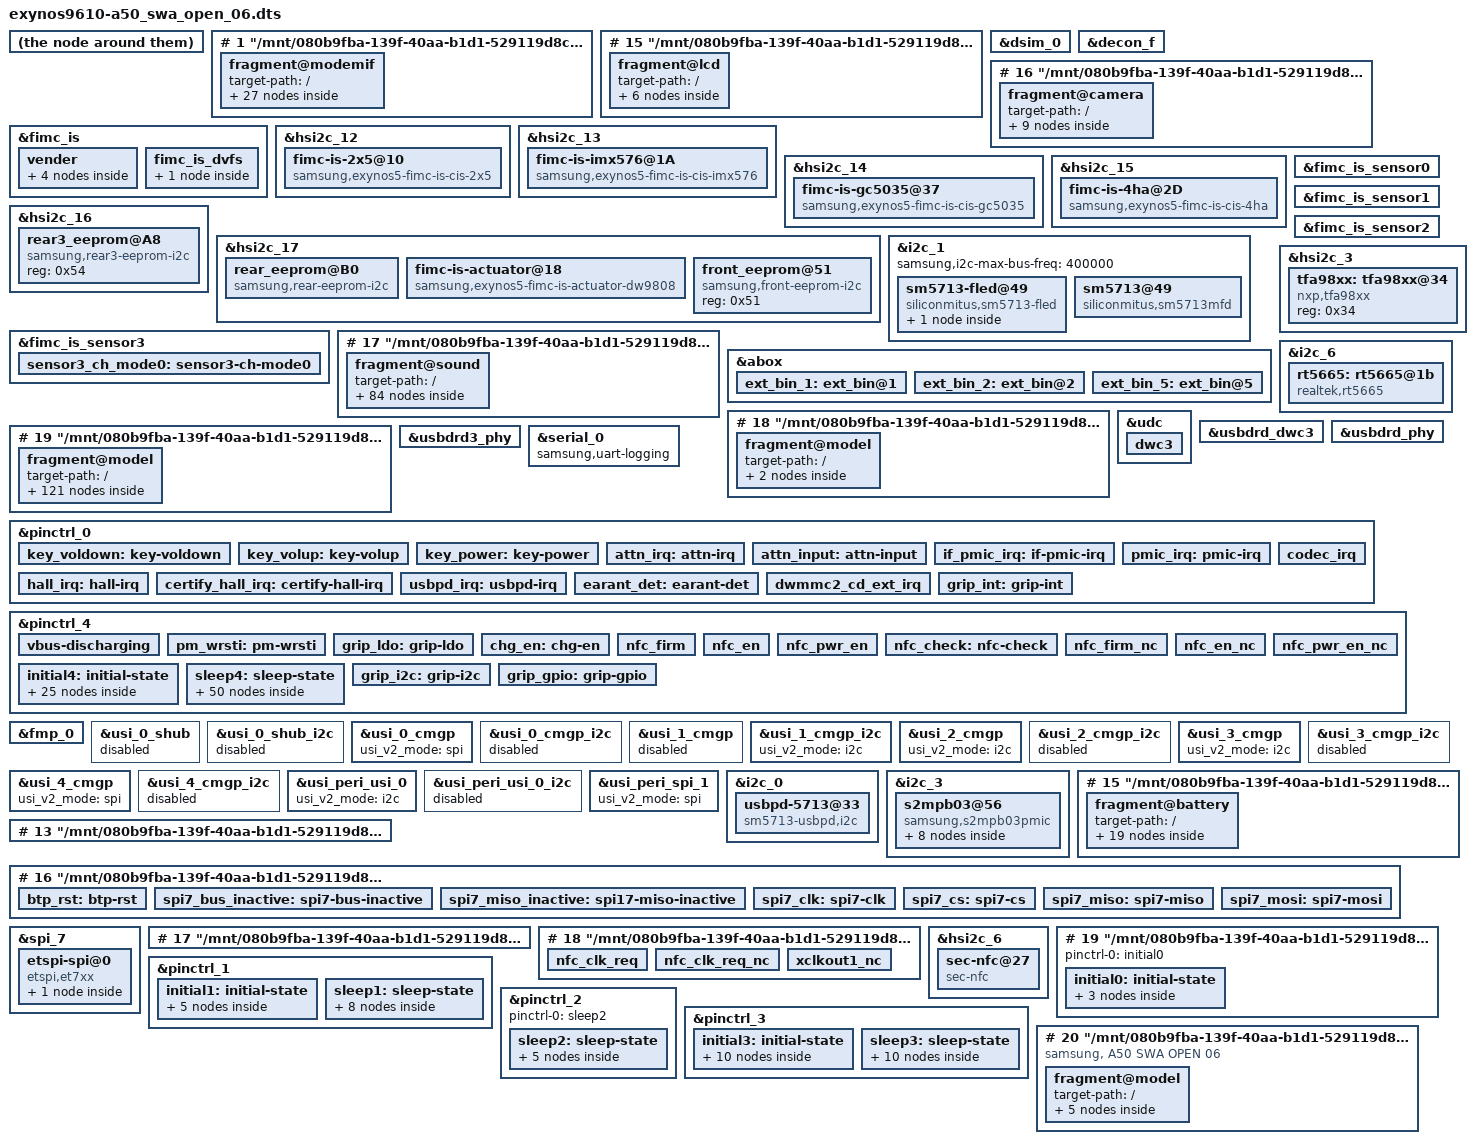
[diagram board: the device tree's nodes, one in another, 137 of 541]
# 1 "/mnt/080b9fba-139f-40aa-b1d1-529119d8c495/develop/Android/Kernel/android_kernel_samsung_universal9610/arch/arm64/boot/dts/exynos/exynos9610-a50_swa_open_06.dts"
# 1 "<built-in>"
# 1 "<command-line>"
# 1 "/mnt/080b9fba-139f-40aa-b1d1-529119d8c495/develop/Android/Kernel/android_kernel_samsung_universal9610/arch/arm64/boot/dts/exynos/exynos9610-a50_swa_open_06.dts"
# 12 "/mnt/080b9fba-139f-40aa-b1d1-529119d8c495/develop/Android/Kernel/android_kernel_samsung_universal9610/arch/arm64/boot/dts/exynos/exynos9610-a50_swa_open_06.dts"
/dts-v1/;
/plugin/;
# 1 "/mnt/080b9fba-139f-40aa-b1d1-529119d8c495/develop/Android/Kernel/android_kernel_samsung_universal9610/arch/arm64/boot/dts/exynos/exynos9610-a50_common.dtsi" 1
# 12 "/mnt/080b9fba-139f-40aa-b1d1-529119d8c495/develop/Android/Kernel/android_kernel_samsung_universal9610/arch/arm64/boot/dts/exynos/exynos9610-a50_common.dtsi"
# 1 "/mnt/080b9fba-139f-40aa-b1d1-529119d8c495/develop/Android/Kernel/android_kernel_samsung_universal9610/include/dt-bindings/camera/fimc_is.h" 1
# 13 "/mnt/080b9fba-139f-40aa-b1d1-529119d8c495/develop/Android/Kernel/android_kernel_samsung_universal9610/arch/arm64/boot/dts/exynos/exynos9610-a50_common.dtsi" 2
# 1 "/mnt/080b9fba-139f-40aa-b1d1-529119d8c495/develop/Android/Kernel/android_kernel_samsung_universal9610/include/dt-bindings/clock/exynos9610.h" 1
# 14 "/mnt/080b9fba-139f-40aa-b1d1-529119d8c495/develop/Android/Kernel/android_kernel_samsung_universal9610/arch/arm64/boot/dts/exynos/exynos9610-a50_common.dtsi" 2
# 1 "/mnt/080b9fba-139f-40aa-b1d1-529119d8c495/develop/Android/Kernel/android_kernel_samsung_universal9610/arch/arm64/boot/dts/exynos/modem-s337ap-sipc-pdata.dtsi" 1
# 12 "/mnt/080b9fba-139f-40aa-b1d1-529119d8c495/develop/Android/Kernel/android_kernel_samsung_universal9610/arch/arm64/boot/dts/exynos/modem-s337ap-sipc-pdata.dtsi"
/ {
 fragment@modemif {
  target-path = "/";
  __overlay__ {
   #address-cells = <2>;
   #size-cells = <1>;

   mif_pdata {

    reg = <0 0x10000 0x0>;

    compatible = "sec_modem,modem_pdata";
    status = "okay";
    interrupts = <0 75 0>;


    mif,name = "s337ap";
    mif,modem_net = <0>;
    mif,modem_type = <10>;
    mif,use_handover = <0>;
    mif,ipc_version = <50>;
    mif,link_types = <0x200>;
    mif,link_name = "shmem";
    mif,link_attrs = <0x7C9>;
    mif,num_iodevs = <23>;


    mif,use_usb_phy = <0>;


    mbx_ap2cp_msg = <0>;
    mbx_cp2ap_msg = <1>;
    mbx_ap2cp_united_status = <2>;
    mbx_cp2ap_united_status = <3>;
    mbx_ap2cp_mif_value = <4>;
    mbx_ap2cp_kerneltime = <9>;
    mbx_cp2ap_pcie_l1ss_disable = <17>;
    mif,int_ap2cp_msg = <0>;
    mif,int_ap2cp_wakeup = <1>;
    mif,int_ap2cp_status = <2>;
    mif,int_ap2cp_active = <3>;

    mif,irq_cp2ap_msg = <0>;
    mif,irq_cp2ap_status = <2>;
    mif,irq_cp2ap_active = <3>;
    mif,irq_cp2ap_wakelock = <8>;
    mif,irq_cp2ap_pcie_l1ss_disable = <9>;
    mif,int_ap2cp_uart_noti = <15>;


    mbx_cp2ap_dvfsreq = <4>;
    mbx_cp2ap_dvfsreq_cpu = <5>;
    mbx_cp2ap_dvfsreq_mif = <6>;
    mbx_cp2ap_dvfsreq_int = <7>;

    mif,irq_cp2ap_perf_req_cpu = <5>;
    mif,irq_cp2ap_perf_req_mif = <6>;
    mif,irq_cp2ap_perf_req_int = <7>;


    sbi_cp_rat_mode_mask = <0x3f>;
    sbi_cp_rat_mode_pos = <26>;
    sbi_cp_evs_mode_mask = <0x1>;
    sbi_cp_evs_mode_pos = <7>;
    sbi_cp2ap_wakelock_mask = <0x1>;
    sbi_cp2ap_wakelock_pos = <6>;
    sbi_lte_active_mask = <0x1>;
    sbi_lte_active_pos = <5>;
    sbi_cp_status_mask = <0xf>;
    sbi_cp_status_pos = <1>;
    sbi_pda_active_mask = <0x1>;
    sbi_pda_active_pos = <5>;
    sbi_ap_status_mask = <0xf>;
    sbi_ap_status_pos = <1>;

    sbi_crash_type_mask = <0xf>;
    sbi_crash_type_pos = <25>;
    sbi_device_type_mask = <0x1f>;
    sbi_device_type_pos = <20>;

    sbi_ext_backtrace_mask = <0x1>;
    sbi_ext_backtrace_pos = <17>;
    sbi_ds_det_mask = <0x3>;
    sbi_ds_det_pos = <14>;
    sbi_sys_rev_mask = <0xff>;
    sbi_sys_rev_pos = <6>;

    sbi_lockval_cp2ap_dvfsreq_endian_mask = <0x1>;
    sbi_lockval_cp2ap_dvfsreq_endian_pos = <31>;
    sbi_lockval_cp2ap_dvfsreq_index_mask = <0x7fff>;
    sbi_lockval_cp2ap_dvfsreq_index_pos = <0>;

    sbi_ap2cp_kerneltime_sec_mask = <0xfff>;
    sbi_ap2cp_kerneltime_sec_pos = <20>;
    sbi_ap2cp_kerneltime_usec_mask = <0xfffff>;
    sbi_ap2cp_kerneltime_usec_pos = <0>;

    sbi_uart_noti_mask = <0x1>;
    sbi_uart_noti_pos = <16>;

    iodevs {
     io_device_0 {
      iod,name = "umts_cass";
      iod,id = <35>;
      iod,format = <1>;
      iod,io_type = <0>;
      iod,links = <0x200>;
      iod,attrs = <0x82>;
      iod,max_tx_size = <2048>;
      iod,ul_num_buffers = <16>;
      iod,ul_buffer_size = <2048>;
      iod,dl_num_buffers = <16>;
      iod,dl_buffer_size = <2048>;
     };
     io_device_1 {
      iod,name = "umts_ipc0";
      iod,id = <235>;
      iod,format = <0>;
      iod,io_type = <0>;
      iod,links = <0x200>;
      iod,attrs = <0x82>;
      iod,app = "RIL";
      iod,ul_num_buffers = <16>;
      iod,ul_buffer_size = <4096>;
      iod,dl_num_buffers = <32>;
      iod,dl_buffer_size = <4096>;
     };
     io_device_2 {
      iod,name = "umts_ipc1";
      iod,id = <236>;
      iod,format = <0>;
      iod,io_type = <0>;
      iod,links = <0x200>;
      iod,attrs = <0x82>;
      iod,app = "RIL";
      iod,ul_num_buffers = <16>;
      iod,ul_buffer_size = <4096>;
      iod,dl_num_buffers = <32>;
      iod,dl_buffer_size = <4096>;
     };
     io_device_3 {
      iod,name = "umts_rfs0";
      iod,id = <245>;
      iod,format = <2>;
      iod,io_type = <0>;
      iod,links = <0x200>;
      iod,attrs = <0x82>;
      iod,app = "RFS";
      iod,ul_num_buffers = <16>;
      iod,ul_buffer_size = <2048>;
      iod,dl_num_buffers = <512>;
      iod,dl_buffer_size = <2048>;
     };
     io_device_4 {
      iod,name = "umts_csd";
      iod,id = <1>;
      iod,format = <1>;
      iod,io_type = <0>;
      iod,links = <0x200>;
      iod,attrs = <0x82>;
      iod,app = "CSVT";
      iod,ul_num_buffers = <32>;
      iod,ul_buffer_size = <2048>;
      iod,dl_num_buffers = <64>;
      iod,dl_buffer_size = <2048>;
     };
     io_device_5 {
      iod,name = "umts_router";
      iod,id = <25>;
      iod,format = <1>;
      iod,io_type = <0>;
      iod,links = <0x200>;
      iod,attrs = <0x82>;
      iod,app = "Data Router";
      iod,max_tx_size = <1550>;
      iod,ul_num_buffers = <16>;
      iod,ul_buffer_size = <2048>;
      iod,dl_num_buffers = <16>;
      iod,dl_buffer_size = <2048>;
     };
     io_device_6 {
      iod,name = "umts_dm0";
      iod,id = <28>;
      iod,format = <1>;
      iod,io_type = <0>;
      iod,links = <0x200>;
      iod,attrs = <0x82>;
      iod,app = "DIAG";
      iod,ul_num_buffers = <16>;
      iod,ul_buffer_size = <2048>;
      iod,dl_num_buffers = <128>;
      iod,dl_buffer_size = <2048>;
     };
     io_device_7 {
      iod,name = "ipc_loopback0";
      iod,id = <244>;
      iod,format = <0>;
      iod,io_type = <0>;
      iod,links = <0x200>;
      iod,attrs = <0x82>;
      iod,app = "CLD";
      iod,ul_num_buffers = <16>;
      iod,ul_buffer_size = <2048>;
      iod,dl_num_buffers = <32>;
      iod,dl_buffer_size = <2048>;
     };
     io_device_8 {
      iod,name = "rmnet0";
      iod,id = <10>;
      iod,format = <1>;
      iod,io_type = <1>;
      iod,links = <0x200>;
      iod,attrs = <0x180>;
      iod,app = "NET";
      iod,ul_num_buffers = <0>;
      iod,ul_buffer_size = <2048>;
      iod,dl_num_buffers = <0>;
      iod,dl_buffer_size = <2048>;
     };
     io_device_9 {
      iod,name = "rmnet1";
      iod,id = <11>;
      iod,format = <1>;
      iod,io_type = <1>;
      iod,links = <0x200>;
      iod,attrs = <0x180>;
      iod,app = "NET";
      iod,ul_num_buffers = <0>;
      iod,ul_buffer_size = <2048>;
      iod,dl_num_buffers = <0>;
      iod,dl_buffer_size = <2048>;
     };
     io_device_10 {
      iod,name = "rmnet2";
      iod,id = <12>;
      iod,format = <1>;
      iod,io_type = <1>;
      iod,links = <0x200>;
      iod,attrs = <0x180>;
      iod,app = "NET";
      iod,ul_num_buffers = <0>;
      iod,ul_buffer_size = <2048>;
      iod,dl_num_buffers = <0>;
      iod,dl_buffer_size = <2048>;
     };
     io_device_11 {
      iod,name = "rmnet3";
      iod,id = <13>;
      iod,format = <1>;
      iod,io_type = <1>;
      iod,links = <0x200>;
      iod,attrs = <0x180>;
      iod,app = "NET";
      iod,ul_num_buffers = <0>;
      iod,ul_buffer_size = <2048>;
      iod,dl_num_buffers = <0>;
      iod,dl_buffer_size = <2048>;
     };
     io_device_12 {
      iod,name = "rmnet4";
      iod,id = <14>;
      iod,format = <1>;
      iod,io_type = <1>;
      iod,links = <0x200>;
      iod,attrs = <0x180>;
      iod,ul_num_buffers = <0>;
      iod,ul_buffer_size = <2048>;
      iod,dl_num_buffers = <0>;
      iod,dl_buffer_size = <2048>;
     };
     io_device_13 {
      iod,name = "rmnet5";
      iod,id = <15>;
      iod,format = <1>;
      iod,io_type = <1>;
      iod,links = <0x200>;
      iod,attrs = <0x180>;
      iod,ul_num_buffers = <0>;
      iod,ul_buffer_size = <2048>;
      iod,dl_num_buffers = <0>;
      iod,dl_buffer_size = <2048>;
     };
     io_device_14 {
      iod,name = "rmnet6";
      iod,id = <16>;
      iod,format = <1>;
      iod,io_type = <1>;
      iod,links = <0x200>;
      iod,attrs = <0x180>;
      iod,ul_num_buffers = <0>;
      iod,ul_buffer_size = <2048>;
      iod,dl_num_buffers = <0>;
      iod,dl_buffer_size = <2048>;
     };
     io_device_15 {
      iod,name = "rmnet7";
      iod,id = <17>;
      iod,format = <1>;
      iod,io_type = <1>;
      iod,links = <0x200>;
      iod,attrs = <0x180>;
      iod,ul_num_buffers = <0>;
      iod,ul_buffer_size = <2048>;
      iod,dl_num_buffers = <0>;
      iod,dl_buffer_size = <2048>;
     };
     io_device_16 {
      iod,name = "multipdp_hiprio";
      iod,id = <0>;
      iod,format = <3>;
      iod,io_type = <2>;
      iod,links = <0x200>;
      iod,attrs = <0x180>;
      iod,app = "RIL";
      iod,ul_num_buffers = <256>;
      iod,ul_buffer_size = <2048>;
      iod,dl_num_buffers = <256>;
      iod,dl_buffer_size = <2048>;
     };
     io_device_17 {
      iod,name = "multipdp";
      iod,id = <0>;
      iod,format = <3>;
      iod,io_type = <2>;
      iod,links = <0x200>;
      iod,attrs = <0x180>;
      iod,app = "RIL";
      iod,ul_num_buffers = <512>;
      iod,ul_buffer_size = <2048>;
      iod,dl_num_buffers = <1024>;
      iod,dl_buffer_size = <2048>;
     };
     io_device_18 {
      iod,name = "umts_boot0";
      iod,id = <215>;
      iod,format = <4>;
      iod,io_type = <0>;
      iod,links = <0x200>;
      iod,attrs = <0x02>;
      iod,app = "CBD";
     };
     io_device_19 {
      iod,name = "umts_ramdump0";
      iod,id = <225>;
      iod,format = <5>;
      iod,io_type = <0>;
      iod,links = <0x200>;
      iod,attrs = <0x202>;
      iod,app = "CBD";
     };
     io_device_20 {
      iod,name = "umts_atc0";
      iod,id = <32>;
      iod,format = <1>;
      iod,io_type = <0>;
      iod,links = <0x200>;
      iod,attrs = <0x882>;
      iod,app = "VCD";
      iod,max_tx_size = <2048>;
      iod,ul_num_buffers = <16>;
      iod,ul_buffer_size = <2048>;
      iod,dl_num_buffers = <128>;
      iod,dl_buffer_size = <2048>;
      iod,option_region = "usa_vzw";
     };
     io_device_21 {
      iod,name = "smd4";
      iod,id = <33>;
      iod,format = <1>;
      iod,io_type = <0>;
      iod,links = <0x200>;
      iod,attrs = <0x882>;
      iod,ul_num_buffers = <16>;
      iod,ul_buffer_size = <2048>;
      iod,dl_num_buffers = <128>;
      iod,dl_buffer_size = <2048>;
      iod,option_region = "kor_single";
     };
     io_device_22 {
      iod,name = "umts_ciq0";
      iod,id = <26>;
      iod,format = <1>;
      iod,io_type = <0>;
      iod,links = <0x200>;
      iod,attrs = <0x882>;
      iod,ul_num_buffers = <16>;
      iod,ul_buffer_size = <2048>;
      iod,dl_num_buffers = <128>;
      iod,dl_buffer_size = <2048>;
      iod,option_region = "usa_spr";
     };
    };
   };

   shmem: shmem@F0000000 {
    compatible = "samsung,exynos-shm_ipc";

    shmem,cp_size = <0x7900000>;
    shmem,vss_size = <0x700000>;
    shmem,ipc_offset = <0x8000000>;
    shmem,ipc_size = <0x800000>;
   };
  };
 };
};
# 15 "/mnt/080b9fba-139f-40aa-b1d1-529119d8c495/develop/Android/Kernel/android_kernel_samsung_universal9610/arch/arm64/boot/dts/exynos/exynos9610-a50_common.dtsi" 2
# 1 "/mnt/080b9fba-139f-40aa-b1d1-529119d8c495/develop/Android/Kernel/android_kernel_samsung_universal9610/arch/arm64/boot/dts/exynos/display-lcd_a50_common.dtsi" 1
# 12 "/mnt/080b9fba-139f-40aa-b1d1-529119d8c495/develop/Android/Kernel/android_kernel_samsung_universal9610/arch/arm64/boot/dts/exynos/display-lcd_a50_common.dtsi"
/ {
 fragment@lcd {
  target-path = "/";
  __overlay__ {
   decon_board: decon_board {
    gpio_lcd_rst = <&gpg1 3 0x1>;
    gpio_lcd_en_3p0 = <&gpg2 4 0x1>;
    gpio_lcd_en_1p8 = <&gpg1 2 0x1>;

    dsim_set_panel_power_enable {
     type =
     "gpio,high", "gpio_lcd_en_1p8",
     "delay,usleep", "1000 1100",
     "gpio,high", "gpio_lcd_en_3p0",
     "delay,usleep", "10000 11000";
    };
    dsim_set_panel_power_disable {
     type =
     "gpio,low", "gpio_lcd_rst",
     "delay,usleep", "10000 11000",
     "gpio,low", "gpio_lcd_en_1p8",
     "delay,usleep", "5000 6000",
     "gpio,low", "gpio_lcd_en_3p0",
     "delay,usleep", "5000 6000";
    };
    dsim_reset_panel {
     type =
     "gpio,high", "gpio_lcd_rst",
     "delay,usleep", "1000 1100",
     "gpio,low", "gpio_lcd_rst",
     "delay,usleep", "1000 1100",
     "gpio,high", "gpio_lcd_rst",
     "delay,usleep", "10000 11000";
    };
   };

   ea8076: ea8076_fhd {
    mode = <2>;
    resolution = <1080 2340>;
    size = <68 147>;
    timing,refresh = <60>;
    timing,h-porch = <2 2 2>;
    timing,v-porch = <15 3 1>;
    timing,dsi-hs-clk = <1200>;
    timing,pmsk = <3 277 1 0>;
    timing,dsi-escape-clk = <16>;
    update_min = <1080 2>;
    mic_en = <0>;
    mic_ratio = <0>;
    mic_ver = <0>;
    type_of_ddi = <1>;
    dsc_en = <0>;
    dsc_cnt = <0>;
    dsc_slice_num = <0>;
    data_lane = <4>;
    cmd_underrun_lp_ref = <2076>;
    mres_en = <0>;
    noncontinuous_clklane = <0>;
   };
  };
 };
};

&dsim_0 {
 lcd_info = <&ea8076>;
 decon_board = <&decon_board>;
};

&decon_f {
 gpio_pcd = <&gpa0 1 0x1>;
 gpio_err = <&gpa1 1 0x1>;
 gpio_con = <&gpa0 7 0x0>;
};
# 16 "/mnt/080b9fba-139f-40aa-b1d1-529119d8c495/develop/Android/Kernel/android_kernel_samsung_universal9610/arch/arm64/boot/dts/exynos/exynos9610-a50_common.dtsi" 2
# 1 "/mnt/080b9fba-139f-40aa-b1d1-529119d8c495/develop/Android/Kernel/android_kernel_samsung_universal9610/arch/arm64/boot/dts/exynos/exynos9610-a50_camera.dtsi" 1
# 14 "/mnt/080b9fba-139f-40aa-b1d1-529119d8c495/develop/Android/Kernel/android_kernel_samsung_universal9610/arch/arm64/boot/dts/exynos/exynos9610-a50_camera.dtsi"
/ {
 fragment@camera {
  target-path = "/";
  __overlay__ {

   fimc_is_sensor_imx576: fimc-fimc_is_sensor_imx576@1A {
    compatible = "samsung,sensor-module-imx576";

    pinctrl-names = "pin0", "pin1", "pin2", "release";
    pinctrl-0 = <>;
    pinctrl-1 = <&fimc_is_mclk0_out>;
    pinctrl-2 = <&fimc_is_mclk0_fn>;
    pinctrl-3 = <>;

    use_pdaf;

    position = <0>;
    id = <0>;
    mclk_ch = <0>;
    sensor_i2c_ch = <2>;

    gpio_mclk = <&gpc2 0 0x1>;
    gpio_reset = <&gpg1 1 0x1>;

    status = "okay";

    af {
     product_name = <19>;
     i2c_addr = <0x18>;
     i2c_ch = <0>;
    };

    flash {
     product_name = <11>;
    };

    internal_vc {
     vc_list = <2 2 0 3 4 0>;
    };
   };

   fimc_is_flash_gpio: fimc-is-flash-gpio@0 {
    compatible = "samsung,sensor-flash-sm5713";
    id = <0>;
    status = "okay";

    torch-gpio = <&gpa1 3 0x1>;
    flash-gpio = <&gpg0 6 0x1>;
   };


   fimc_is_module_gc5035: fimc-is_sensor_gc5035@37 {
    compatible = "samsung,sensor-module-gc5035";

    pinctrl-names = "pin0", "pin1", "pin2", "release";
    pinctrl-0 = <>;
    pinctrl-1 = <&fimc_is_mclk0_out>;
    pinctrl-2 = <&fimc_is_mclk0_fn>;
    pinctrl-3 = <>;

    position = <2>;
    id = <2>;
    mclk_ch = <0>;

    gpio_mclk = <&gpc2 0 0x1>;
    gpio_reset = <&gpg0 7 0x1>;
    status = "okay";
   };


   fimc_is_sensor_4ha: fimc-is_sensor_4ha@6C {
    compatible = "samsung,sensor-module-4ha";

    pinctrl-names = "pin0", "pin1", "pin2", "release";
    pinctrl-0 = <>;
    pinctrl-1 = <&fimc_is_mclk2_out>;
    pinctrl-2 = <&fimc_is_mclk2_fn>;
    pinctrl-3 = <>;

    position = <4>;
    id = <3>;
    mclk_ch = <2>;

    gpio_mclk = <&gpc2 2 0x1>;
    gpio_reset = <&gpg1 4 0x1>;
    gpio_cam_2p8_en = <&gpm22 0 0x1>;
    status = "okay";
   };


   fimc_is_sensor_2x5: fimc-is_sensor_2x5@10 {
    compatible = "samsung,sensor-module-2x5";

    pinctrl-names = "pin0", "pin1", "pin2", "release";
    pinctrl-0 = <>;
    pinctrl-1 = <&fimc_is_mclk1_out>;
    pinctrl-2 = <&fimc_is_mclk1_fn>;
    pinctrl-3 = <>;

    position = <1>;
    id = <1>;
    mclk_ch = <1>;
    sensor_i2c_ch = <1>;

    gpio_mclk = <&gpc2 1 0x1>;
    gpio_reset = <&gpg1 7 0x1>;

    status = "okay";
   };

  };
 };
};



&fimc_is {
 vender {
  rear_sensor_id = <115>;
  front_sensor_id = <60>;
  rear2_sensor_id = <210>;
  rear3_sensor_id = <39>;
  need_i2c_config;
  use_module_check;
  check_sensor_vendor;
  max_supported_camera = <6>;
  supported_cameraId = <0 1 20 23 50 52>;


  max_camera_num = <4>;
  camera_info0 {
   isp = <0>;
   cal_memory = <2>;
   read_version = <0>;
   core_voltage = <0>;
   upgrade = <0>;
   companion = <0>;
   ois = <0>;
   valid = <1>;
   dual_open = <0>;
   position = <0>;
  };
  camera_info1 {
   isp = <0>;
   cal_memory = <2>;
   read_version = <0>;
   core_voltage = <0>;
   upgrade = <0>;
   companion = <0>;
   ois = <0>;
   valid = <1>;
   dual_open = <0>;
   position = <1>;
  };
  camera_info2 {
   isp = <0>;
   cal_memory = <2>;
   read_version = <0>;
   core_voltage = <0>;
   upgrade = <0>;
   companion = <0>;
   ois = <0>;
   valid = <1>;
   dual_open = <1>;
   position = <2>;
  };
  camera_info3 {
   isp = <0>;
   cal_memory = <2>;
   read_version = <0>;
   core_voltage = <0>;
   upgrade = <0>;
   companion = <0>;
   ois = <0>;
   valid = <1>;
   dual_open = <0>;
   position = <4>;
  };
 };

 fimc_is_dvfs {
# 225 "/mnt/080b9fba-139f-40aa-b1d1-529119d8c495/develop/Android/Kernel/android_kernel_samsung_universal9610/arch/arm64/boot/dts/exynos/exynos9610-a50_camera.dtsi"
  table0 {
   desc = "dvfs table v0.0 for 16M/8M";

   default_int_cam = <690000>;
   default_cam = <690000>;
   default_mif = <2093000>;
   default_int = <100000>;
   default_hpg = <1>;

   front_preview_int_cam = <660000>;
   front_preview_cam = <680000>;
   front_preview_mif = <1352000>;
   front_preview_int = <100000>;
   front_preview_hpg = <1>;

   front_preview_full_int_cam = <680000>;
   front_preview_full_cam = <680000>;
   front_preview_full_mif = <1794000>;
   front_preview_full_int = <100000>;
   front_preview_full_hpg = <1>;

   front_capture_int_cam = <680000>;
   front_capture_cam = <680000>;
   front_capture_mif = <1794000>;
   front_capture_int = <100000>;
   front_capture_hpg = <1>;

   front_video_int_cam = <660000>;
   front_video_cam = <680000>;
   front_video_mif = <1352000>;
   front_video_int = <100000>;
   front_video_hpg = <1>;

   front_video_capture_int_cam = <670000>;
   front_video_capture_cam = <680000>;
   front_video_capture_mif = <1794000>;
   front_video_capture_int = <100000>;
   front_video_capture_hpg = <1>;

   front_vt1_int_cam = <660000>;
   front_vt1_cam = <680000>;
   front_vt1_mif = <1014000>;
   front_vt1_int = <100000>;
   front_vt1_hpg = <1>;

   front_vt2_int_cam = <660000>;
   front_vt2_cam = <680000>;
   front_vt2_mif = <1014000>;
   front_vt2_int = <100000>;
   front_vt2_hpg = <1>;

   front_vt4_int_cam = <660000>;
   front_vt4_cam = <680000>;
   front_vt4_mif = <1014000>;
   front_vt4_int = <100000>;
   front_vt4_hpg = <1>;

   rear2_preview_fhd_int_cam = <660000>;
   rear2_preview_fhd_cam = <650000>;
   rear2_preview_fhd_mif = <1352000>;
   rear2_preview_fhd_int = <100000>;
   rear2_preview_fhd_hpg = <1>;

   rear2_capture_int_cam = <660000>;
   rear2_capture_cam = <660000>;
   rear2_capture_mif = <1539000>;
   rear2_capture_int = <100000>;
   rear2_capture_hpg = <1>;

   rear3_preview_int_cam = <660000>;
   rear3_preview_cam = <660000>;
   rear3_preview_mif = <1352000>;
   rear3_preview_int = <100000>;
   rear3_preview_hpg = <1>;

   rear3_capture_int_cam = <660000>;
   rear3_capture_cam = <660000>;
   rear3_capture_mif = <1539000>;
   rear3_capture_int = <100000>;
   rear3_capture_hpg = <1>;

   rear3_video_int_cam = <660000>;
   rear3_video_cam = <660000>;
   rear3_video_mif = <1352000>;
   rear3_video_int = <100000>;
   rear3_video_hpg = <1>;

   rear3_video_capture_int_cam = <660000>;
   rear3_video_capture_cam = <660000>;
   rear3_video_capture_mif = <1539000>;
   rear3_video_capture_int = <100000>;
   rear3_video_capture_hpg = <1>;

   rear_preview_fhd_int_cam = <660000>;
   rear_preview_fhd_cam = <680000>;
   rear_preview_fhd_mif = <1352000>;
   rear_preview_fhd_int = <100000>;
   rear_preview_fhd_hpg = <1>;

   rear_preview_hd_int_cam = <660000>;
   rear_preview_hd_cam = <680000>;
   rear_preview_hd_mif = <1352000>;
   rear_preview_hd_int = <100000>;
   rear_preview_hd_hpg = <1>;

   rear_preview_uhd_int_cam = <670000>;
   rear_preview_uhd_cam = <680000>;
   rear_preview_uhd_mif = <1539000>;
   rear_preview_uhd_int = <100000>;
   rear_preview_uhd_hpg = <1>;

   rear_preview_full_int_cam = <680000>;
   rear_preview_full_cam = <680000>;
   rear_preview_full_mif = <1794000>;
   rear_preview_full_int = <100000>;
   rear_preview_full_hpg = <1>;

   rear_capture_int_cam = <680000>;
   rear_capture_cam = <680000>;
   rear_capture_mif = <1794000>;
   rear_capture_int = <100000>;
   rear_capture_hpg = <1>;

   rear_video_fhd_int_cam = <660000>;
   rear_video_fhd_cam = <680000>;
   rear_video_fhd_mif = <1352000>;
   rear_video_fhd_int = <100000>;
   rear_video_fhd_hpg = <1>;

   rear_video_hd_int_cam = <660000>;
   rear_video_hd_cam = <680000>;
   rear_video_hd_mif = <1352000>;
   rear_video_hd_int = <100000>;
   rear_video_hd_hpg = <1>;

   rear_video_uhd_int_cam = <670000>;
   rear_video_uhd_cam = <680000>;
   rear_video_uhd_mif = <1539000>;
   rear_video_uhd_int = <100000>;
   rear_video_uhd_hpg = <1>;

   rear_video_fhd_capture_int_cam = <670000>;
   rear_video_fhd_capture_cam = <680000>;
   rear_video_fhd_capture_mif = <1539000>;
   rear_video_fhd_capture_int = <100000>;
   rear_video_fhd_capture_hpg = <1>;

   rear_video_hd_capture_int_cam = <670000>;
   rear_video_hd_capture_cam = <680000>;
   rear_video_hd_capture_mif = <1539000>;
   rear_video_hd_capture_int = <100000>;
   rear_video_hd_capture_hpg = <1>;

   rear_video_uhd_capture_int_cam = <680000>;
   rear_video_uhd_capture_cam = <680000>;
   rear_video_uhd_capture_mif = <1794000>;
   rear_video_uhd_capture_int = <100000>;
   rear_video_uhd_capture_hpg = <1>;

   dual_preview_int_cam = <660000>;
   dual_preview_cam = <680000>;
   dual_preview_mif = <1352000>;
   dual_preview_int = <100000>;
   dual_preview_hpg = <1>;

   dual_capture_int_cam = <680000>;
   dual_capture_cam = <680000>;
   dual_capture_mif = <1794000>;
   dual_capture_int = <100000>;
   dual_capture_hpg = <1>;

   dual_video_fhd_int_cam = <660000>;
   dual_video_fhd_cam = <680000>;
   dual_video_fhd_mif = <1352000>;
   dual_video_fhd_int = <100000>;
   dual_video_fhd_hpg = <1>;

   dual_video_fhd_capture_int_cam = <670000>;
   dual_video_fhd_capture_cam = <680000>;
   dual_video_fhd_capture_mif = <1539000>;
   dual_video_fhd_capture_int = <100000>;
   dual_video_fhd_capture_hpg = <1>;

   dual_video_uhd_int_cam = <670000>;
   dual_video_uhd_cam = <680000>;
   dual_video_uhd_mif = <1539000>;
   dual_video_uhd_int = <100000>;
   dual_video_uhd_hpg = <1>;

   dual_video_uhd_capture_int_cam = <680000>;
   dual_video_uhd_capture_cam = <680000>;
   dual_video_uhd_capture_mif = <1794000>;
   dual_video_uhd_capture_int = <100000>;
   dual_video_uhd_capture_hpg = <1>;

   dual_sync_preview_int_cam = <670000>;
   dual_sync_preview_cam = <680000>;
   dual_sync_preview_mif = <1539000>;
   dual_sync_preview_int = <100000>;
   dual_sync_preview_hpg = <1>;

   dual_sync_capture_int_cam = <680000>;
   dual_sync_capture_cam = <680000>;
   dual_sync_capture_mif = <2002000>;
   dual_sync_capture_int = <100000>;
   dual_sync_capture_hpg = <1>;

   dual_sync_preview_whd_int_cam = <680000>;
   dual_sync_preview_whd_cam = <680000>;
   dual_sync_preview_whd_mif = <1539000>;
   dual_sync_preview_whd_int = <100000>;
   dual_sync_preview_whd_hpg = <1>;

   dual_sync_whd_capture_int_cam = <680000>;
   dual_sync_whd_capture_cam = <680000>;
   dual_sync_whd_capture_mif = <2002000>;
   dual_sync_whd_capture_int = <100000>;
   dual_sync_whd_capture_hpg = <1>;

   dual_sync_video_fhd_int_cam = <670000>;
   dual_sync_video_fhd_cam = <680000>;
   dual_sync_video_fhd_mif = <1539000>;
   dual_sync_video_fhd_int = <100000>;
   dual_sync_video_fhd_hpg = <1>;

   dual_sync_video_fhd_capture_int_cam = <670000>;
   dual_sync_video_fhd_capture_cam = <680000>;
   dual_sync_video_fhd_capture_mif = <2002000>;
   dual_sync_video_fhd_capture_int = <100000>;
   dual_sync_video_fhd_capture_hpg = <1>;

   dual_sync_video_uhd_int_cam = <680000>;
   dual_sync_video_uhd_cam = <680000>;
   dual_sync_video_uhd_mif = <2002000>;
   dual_sync_video_uhd_int = <100000>;
   dual_sync_video_uhd_hpg = <1>;

   dual_sync_video_uhd_capture_int_cam = <680000>;
   dual_sync_video_uhd_capture_cam = <680000>;
   dual_sync_video_uhd_capture_mif = <2002000>;
   dual_sync_video_uhd_capture_int = <100000>;
   dual_sync_video_uhd_capture_hpg = <1>;

   preview_high_speed_fps_int_cam = <680000>;
   preview_high_speed_fps_cam = <680000>;
   preview_high_speed_fps_mif = <2093000>;
   preview_high_speed_fps_int = <100000>;
   preview_high_speed_fps_hpg = <1>;

   video_high_speed_60fps_int_cam = <680000>;
   video_high_speed_60fps_cam = <680000>;
   video_high_speed_60fps_mif = <2093000>;
   video_high_speed_60fps_int = <100000>;
   video_high_speed_60fps_hpg = <1>;

   video_high_speed_120fps_int_cam = <680000>;
   video_high_speed_120fps_cam = <680000>;
   video_high_speed_120fps_mif = <2093000>;
   video_high_speed_120fps_int = <100000>;
   video_high_speed_120fps_hpg = <1>;

   video_high_speed_240fps_int_cam = <680000>;
   video_high_speed_240fps_cam = <680000>;
   video_high_speed_240fps_mif = <2093000>;
   video_high_speed_240fps_int = <100000>;
   video_high_speed_240fps_hpg = <1>;

   video_high_speed_480fps_int_cam = <690000>;
   video_high_speed_480fps_cam = <690000>;
   video_high_speed_480fps_mif = <2093000>;
   video_high_speed_480fps_int = <667000>;
   video_high_speed_480fps_hpg = <1>;

   video_high_speed_60fps_capture_int_cam = <690000>;
   video_high_speed_60fps_capture_cam = <690000>;
   video_high_speed_60fps_capture_mif = <2093000>;
   video_high_speed_60fps_capture_int = <100000>;
   video_high_speed_60fps_capture_hpg = <1>;

   ext_front_int_cam = <690000>;
   ext_front_cam = <690000>;
   ext_front_mif = <2093000>;
   ext_front_int = <100000>;
   ext_front_hpg = <1>;

   ext_secure_int_cam = <690000>;
   ext_secure_cam = <690000>;
   ext_secure_mif = <2093000>;
   ext_secure_int = <100000>;
   ext_secure_hpg = <1>;

   max_int_cam = <690000>;
   max_cam = <690000>;
   max_mif = <2093000>;
   max_int = <667000>;
   max_hpg = <1>;
  };
 };
};


&hsi2c_12 {
 #address-cells = <1>;
 #size-cells = <0>;
 gpios = <&gpc0 0 0 &gpc0 1 0>;
 status = "okay";
 clock-frequency = <1000000>;
 samsung,reset-before-trans;
 samsung,fast-plus-mode;

 pinctrl-names = "default","on_i2c","off_i2c";
 pinctrl-0 = <&hsi2c12_bus>;
 pinctrl-1 = <&hsi2c12_bus>;
 pinctrl-2 = <&hsi2c12_bus>;

 fimc-is-2x5@10 {
  compatible = "samsung,exynos5-fimc-is-cis-2x5";
  reg = <0x10>;
  id = <1>;
  sensor_f_number = <200>;
  setfile = "setA";
 };
};


&hsi2c_13 {
 #address-cells = <1>;
 #size-cells = <0>;
 gpios = <&gpc0 2 0 &gpc0 3 0>;
 status = "okay";
 clock-frequency = <1000000>;
 samsung,reset-before-trans;
 samsung,fast-plus-mode;

 pinctrl-names = "default","on_i2c","off_i2c";
 pinctrl-0 = <&hsi2c13_bus>;
 pinctrl-1 = <&hsi2c13_bus>;
 pinctrl-2 = <&hsi2c13_bus>;

 fimc-is-imx576@1A {
  compatible = "samsung,exynos5-fimc-is-cis-imx576";
  reg = <0x1A>;
  id = <0>;
  sensor_f_number = <170>;
  setfile = "setA";
 };
};


&hsi2c_14 {
 #address-cells = <1>;
 #size-cells = <0>;
 gpios = <&gpc0 4 0 &gpc0 5 0>;
 status = "okay";
 clock-frequency = <400000>;
 samsung,reset-before-trans;

 pinctrl-names = "default","on_i2c","off_i2c";
 pinctrl-0 = <&hsi2c14_bus>;
 pinctrl-1 = <&hsi2c14_bus>;
 pinctrl-2 = <&hsi2c14_bus>;

 fimc-is-gc5035@37 {
  compatible = "samsung,exynos5-fimc-is-cis-gc5035";
  reg = <0x37>;
  id = <2>;
  sensor_f_number = <220>;
  setfile = "setB";
 };
};


&hsi2c_15 {
 #address-cells = <1>;
 #size-cells = <0>;
 gpios = <&gpc0 6 0 &gpc0 7 0>;
 status = "okay";
 clock-frequency = <400000>;
 samsung,reset-before-trans;

 pinctrl-names = "default","on_i2c","off_i2c";
 pinctrl-0 = <&hsi2c15_bus>;
 pinctrl-1 = <&hsi2c15_bus>;
 pinctrl-2 = <&hsi2c15_bus>;

 fimc-is-4ha@2D {
  compatible = "samsung,exynos5-fimc-is-cis-4ha";
  reg = <0x2D>;
  id = <3>;
  sensor_f_number = <220>;
  setfile = "setB";
 };
};


&hsi2c_16 {
 #address-cells = <1>;
 #size-cells = <0>;
 gpios = <&gpc1 1 0 &gpc1 0 0>;
 status = "okay";
 clock-frequency = <400000>;
 samsung,reset-before-trans;

 pinctrl-names = "default","on_i2c","off_i2c";
 pinctrl-0 = <&hsi2c16_bus>;
 pinctrl-1 = <&hsi2c16_bus>;
 pinctrl-2 = <&hsi2c16_bus>;

 rear3_eeprom@A8 {
  compatible = "samsung,rear3-eeprom-i2c";
  reg = <0x54>;
 };
};


&hsi2c_17 {
 #address-cells = <1>;
 #size-cells = <0>;
 gpios = <&gpc1 3 0 &gpc1 2 0>;
 status = "okay";
 clock-frequency = <400000>;
 samsung,reset-before-trans;

 pinctrl-names = "default","on_i2c","off_i2c";
 pinctrl-0 = <&hsi2c17_bus>;
 pinctrl-1 = <&hsi2c17_bus>;
 pinctrl-2 = <&hsi2c17_bus>;

 rear_eeprom@B0 {
  compatible = "samsung,rear-eeprom-i2c";
  reg = <0x58>;

  use_common_rom_position = <2>;
 };

 fimc-is-actuator@18 {
  compatible = "samsung,exynos5-fimc-is-actuator-dw9808";
  reg = <0x0C>;
  id = <0>;
  place = <0>;
 };

 front_eeprom@51 {
  compatible = "samsung,front-eeprom-i2c";
  reg = <0x51>;
 };
};

&i2c_1 {
 sm5713-fled@49 {
  compatible = "siliconmitus,sm5713-fled";
  sm5713-fled@0 {
   id=<0>;
   status = "okay";
   flash-en-gpio = <&gpg0 6 0>;
   torch-en-gpio = <&gpa1 3 0>;
   flash-brightness = <0xF>;
   preflash-brightness = <0x4>;
   torch-brightness = <0x4>;
   timeout = <0xff>;
  };
 };
};

&fimc_is_sensor0 {
 scenario = <0>;
 id = <0>;
 csi_ch = <0>;
 dma_ch = <0 0 0 0 0 0 2 0>;
 vc_ch = <0 1 2 3 0 1 0 3>;
 flite_ch = <100>;
 is_bns = <0>;
 csi_mux = <2>;
 multi_ch = <2>;
 use_ssvc2_internal;
 use_ssvc3_internal;
 status = "okay";
};

&fimc_is_sensor1 {
 phys = <&mipi_phy_csis_m2s4s4s2 1>;

 scenario = <0>;
 id = <2>;
 csi_ch = <1>;
 dma_ch = <1 1 1 1 2 2 2 2>;
 vc_ch = <0 1 2 3 1 2 1 3>;
 flite_ch = <100>;
 is_bns = <0>;
 csi_mux = <2>;
 multi_ch = <2>;
 status = "okay";
};

&fimc_is_sensor2 {
 scenario = <0>;
 id = <1>;
 csi_ch = <2>;
 dma_ch = <3 2 2 2>;
 vc_ch = <1 1 2 3>;
 flite_ch = <100>;
 is_bns = <0>;
 csi_mux = <2>;
 multi_ch = <0>;
 status = "okay";
};

&fimc_is_sensor3 {
 reg = <0x0 0x14410700 0x100>,
  <0x0 0x14410000 0x700>;
 reg-names = "phy", "csi";
 interrupts = <0 326 0>,
  <0 332 0>,
  <0 332 0>,
  <0 332 0>,
  <0 332 0>;
 interrupt-names = "csi",
  "mode0_VC0", "mode0_VC1","mode0_VC2","mode0_VC3";
 phys = <&mipi_phy_csis_m2s4s4s2 0>;

 scenario = <0>;
 id = <3>;
 csi_ch = <1>;
 dma_ch = <1 1 1 1>;
 vc_ch = <0 1 2 3>;
 flite_ch = <100>;
 is_bns = <0>;
 csi_mux = <0>;
 multi_ch = <2>;
 status = "okay";


 sensor3_ch_mode0: sensor3-ch-mode0 {
  reg = <0x14460000 0x100>,
   <0x14460400 0x100>,
   <0x14460100 0x100>,
   <0x14460400 0x100>,
   <0x14460200 0x100>,
   <0x14460400 0x100>,
   <0x14460300 0x100>,
   <0x14460400 0x100>;
 };
};
# 17 "/mnt/080b9fba-139f-40aa-b1d1-529119d8c495/develop/Android/Kernel/android_kernel_samsung_universal9610/arch/arm64/boot/dts/exynos/exynos9610-a50_common.dtsi" 2
# 1 "/mnt/080b9fba-139f-40aa-b1d1-529119d8c495/develop/Android/Kernel/android_kernel_samsung_universal9610/arch/arm64/boot/dts/exynos/exynos9610-a50_sound.dtsi" 1
# 12 "/mnt/080b9fba-139f-40aa-b1d1-529119d8c495/develop/Android/Kernel/android_kernel_samsung_universal9610/arch/arm64/boot/dts/exynos/exynos9610-a50_sound.dtsi"
/ {
 fragment@sound {
  target-path = "/";
  __overlay__ {
   dummy_audio_codec: audio_codec_dummy {
    status = "okay";
    compatible = "snd-soc-dummy";
   };

   dummy_audio_cpu: audio_cpu_dummy {
    compatible = "samsung,dummy-cpu";
    status = "okay";
   };

   sound {
    status = "okay";
    compatible = "samsung,exynos9610-audio";

    clock-names = "xclkout";
    clocks = <&clock ((800) + 1)>;
    pinctrl-names = "default";
    pinctrl-0 = <&xclkout0 &earant_det>;

    samsung,routing =
     "HEADSETMIC", "MICBIAS1",
     "MAINMIC", "MICBIAS2",
     "SUBMIC", "MICBIAS3",
     "IN1P", "HEADSETMIC",
     "IN1N", "HEADSETMIC",
     "IN3P", "MAINMIC",
     "IN3N", "MAINMIC",
     "IN4P", "SUBMIC",
     "IN4N", "SUBMIC",
     "RECEIVER", "MONOOUT",
     "RECEIVER", "MONOOUT",
     "HEADPHONE", "HPOL",
     "HEADPHONE", "HPOR",
     "VOUTPUT", "ABOX UAIF0 Playback",
     "SPEAKER", "ABOX UAIF2 Playback",
     "VOUTPUTCALL", "ABOX SIFS0 Playback",
     "BLUETOOTH SPK", "ABOX SIFS2 Playback",
     "ABOX SPDY Capture", "FM IN",
     "ABOX SIFS2 Capture", "BLUETOOTH MIC",
     "ABOX SIFS0 Capture", "VINPUTCALL";

    samsung,codec = <&abox &abox_uaif_0 &abox_uaif_1 &abox_uaif_2
     &abox_uaif_4 &abox_dsif &abox_spdy>;
    samsung,prefix = "ABOX", "ABOX", "ABOX", "ABOX",
     "ABOX", "ABOX", "ABOX";
    samsung,aux = <&abox_effect &abox_bt>;

    rdma@0 {
     cpu {
      sound-dai = <&abox 0>;
     };
     platform {
      sound-dai = <&abox_rdma_0>;
     };
     codec {
      sound-dai = <&dummy_audio_codec>;
     };
    };
    rdma@1 {
     cpu {
      sound-dai = <&abox 1>;
     };
     platform {
      sound-dai = <&abox_rdma_1>;
     };
     codec {
      sound-dai = <&dummy_audio_codec>;
     };
    };
    rdma@2 {
     cpu {
      sound-dai = <&abox 2>;
     };
     platform {
      sound-dai = <&abox_rdma_2>;
     };
     codec {
      sound-dai = <&dummy_audio_codec>;
     };
    };
    rdma@3 {
     cpu {
      sound-dai = <&abox 3>;
     };
     platform {
      sound-dai = <&abox_rdma_3>;
     };
     codec {
      sound-dai = <&dummy_audio_codec>;
     };
    };
    rdma@4 {
     cpu {
      sound-dai = <&abox 4>;
     };
     platform {
      sound-dai = <&abox_rdma_4>;
     };
     codec {
      sound-dai = <&dummy_audio_codec>;
     };
    };
    rdma@5 {
     cpu {
      sound-dai = <&abox 5>;
     };
     platform {
      sound-dai = <&abox_rdma_5>;
     };
     codec {
      sound-dai = <&dummy_audio_codec>;
     };
    };
    rdma@6 {
     cpu {
      sound-dai = <&abox 6>;
     };
     platform {
      sound-dai = <&abox_rdma_6>;
     };
     codec {
      sound-dai = <&dummy_audio_codec>;
     };
    };
    rdma@7 {
     cpu {
      sound-dai = <&abox 7>;
     };
     platform {
      sound-dai = <&abox_rdma_7>;
     };
     codec {
      sound-dai = <&dummy_audio_codec>;
     };
    };
    wdma@0 {
     cpu {
      sound-dai = <&abox 8>;
     };
     platform {
      sound-dai = <&abox_wdma_0>;
     };
     codec {
      sound-dai = <&dummy_audio_codec>;
     };
    };
    wdma@1 {
     cpu {
      sound-dai = <&abox 9>;
     };
     platform {
      sound-dai = <&abox_wdma_1>;
     };
     codec {
      sound-dai = <&dummy_audio_codec>;
     };
    };
    wdma@2 {
     cpu {
      sound-dai = <&abox 10>;
     };
     platform {
      sound-dai = <&abox_wdma_2>;
     };
     codec {
      sound-dai = <&dummy_audio_codec>;
     };
    };
    wdma@3 {
     cpu {
      sound-dai = <&abox 11>;
     };
     platform {
      sound-dai = <&abox_wdma_3>;
     };
     codec {
      sound-dai = <&dummy_audio_codec>;
     };
    };
    wdma@4 {
     cpu {
      sound-dai = <&abox 12>;
     };
     platform {
      sound-dai = <&abox_wdma_4>;
     };
     codec {
      sound-dai = <&dummy_audio_codec>;
     };
    };
# 216 "/mnt/080b9fba-139f-40aa-b1d1-529119d8c495/develop/Android/Kernel/android_kernel_samsung_universal9610/arch/arm64/boot/dts/exynos/exynos9610-a50_sound.dtsi"
    uaif@0 {
     format = "i2s";
     cpu {
      sound-dai = <&abox_uaif_0>;
     };
     codec {
      sound-dai = <&rt5665 0>;
     };
    };
    uaif@1 {
     format = "i2s";
     cpu {
      sound-dai = <&abox_uaif_1>;
     };
     codec {
      sound-dai = <&dummy_audio_codec>;
     };
    };
    uaif@2 {
     format = "i2s";
     cpu {
      sound-dai = <&abox_uaif_2>;
     };
     platform {
      sound-dai = <&abox_synchronized_ipc 0>;
     };
     codec {
      sound-dai = <&tfa98xx 0>;
     };
    };
    uaif@4 {
     format = "i2s";
     bitclock-master;
     frame-master;
     cpu {
      sound-dai = <&abox_uaif_4>;
     };
     codec {
      sound-dai = <&dummy_audio_codec>;
     };
    };
    dsif@0 {
     format = "pdm";
     cpu {
      sound-dai = <&abox_dsif>;
     };
     codec {
      sound-dai = <&dummy_audio_codec>;
     };
    };
    spdy@0 {
     cpu {
      sound-dai = <&abox_spdy>;
     };
     codec {
      sound-dai = <&dummy_audio_codec>;
     };
    };
    sifs0@0 {
     cpu {
      sound-dai = <&abox 13>;
     };
     codec {
      sound-dai = <&dummy_audio_codec>;
     };
    };
    sifs1@0 {
     cpu {
      sound-dai = <&abox 14>;
     };
     codec {
      sound-dai = <&dummy_audio_codec>;
     };
    };
    sifs2@0 {
     cpu {
      sound-dai = <&abox 15>;
     };
     codec {
      sound-dai = <&dummy_audio_codec>;
     };
    };
   };
  };
 };
};

&abox {
 /delete-node/ ext_bin@1;
 ext_bin_1: ext_bin@1 {
  status = "okay";
  samsung,name = "AP_AUDIO_SLSI.bin";
  samsung,area = <1>;
  samsung,offset = <0x7F0000>;
 };
 /delete-node/ ext_bin@2;
 ext_bin_2: ext_bin@2 {
  status = "okay";
  samsung,name = "APBargeIn_AUDIO_SLSI.bin";
  samsung,area = <1>;
  samsung,offset = <0x7EC000>;
 };
 /delete-node/ ext_bin@5;
 ext_bin_5: ext_bin@5 {
  status = "okay";
  samsung,name = "APBiBF_AUDIO_SLSI.bin";
  samsung,area = <1>;
  samsung,offset = <0x7EF000>;
 };
};

&hsi2c_3 {
 #address-cells = <1>;
 #size-cells = <0>;
 status = "okay";
 tfa98xx: tfa98xx@34 {
  compatible = "nxp,tfa98xx";
  #sound-dai-cells = <1>;
  reg = <0x34>;
 };
};

&i2c_6 {
 #address-cells = <1>;
 #size-cells = <0>;
 status = "okay";
 rt5665: rt5665@1b {
  compatible = "realtek,rt5665";
  reg = <0x1b>;
  pinctrl-names = "default";
  pinctrl-0 = <&codec_irq>;
  interrupt-parent = <&gpa1>;
  interrupts = <2 0 0>;
  #sound-dai-cells = <1>;
  realtek,in1-differential;
  realtek,in3-differential;
  realtek,in4-differential;
  realtek,jd-src = <2>;
  realtek,dmic2-data-pin =<2>;
  realtek,sar-hs-type = <700>;
  realtek,sar-pb-vth0 = <95>;
  realtek,sar-pb-vth1 = <139>;
  realtek,sar-pb-vth2 = <246>;
  realtek,sar-pb-vth3 = <580>;
  imp_table = <

   0x0000 0x000d 3 6
   0x000e 0x0019 1 6
   0x001a 0x0035 0 6
   0x0036 0x0067 0 6
   0x0068 0xffff 0 6
  >;

  realtek,offset-comp = <0x0078 0x0090 0x00b0 0x00c0
     0x00f0 0x0110 0x0130 0x0180
     0x01e0 0x0200 0x02a0 0x0300
     0x03a0 0x0400 0x0500 0x0600>;
  realtek,offset-comp-r = <0x001a 0x001f 0x0020 0x002a
     0x0030 0x0040 0x0050 0x0060
     0x006f 0x007f 0x00a0 0x00b0
     0x00cf 0x0100 0x0120 0x0160>;
  realtek,regulator_1v8 = <&l42_reg>;
  realtek,regulator_3v3 = <&l40_reg>;
 };
};
# 18 "/mnt/080b9fba-139f-40aa-b1d1-529119d8c495/develop/Android/Kernel/android_kernel_samsung_universal9610/arch/arm64/boot/dts/exynos/exynos9610-a50_common.dtsi" 2
# 1 "/mnt/080b9fba-139f-40aa-b1d1-529119d8c495/develop/Android/Kernel/android_kernel_samsung_universal9610/arch/arm64/boot/dts/exynos/exynos9610-a50_mst_03.dtsi" 1
# 13 "/mnt/080b9fba-139f-40aa-b1d1-529119d8c495/develop/Android/Kernel/android_kernel_samsung_universal9610/arch/arm64/boot/dts/exynos/exynos9610-a50_mst_03.dtsi"
/ {
 fragment@model {
  target-path = "/";
  __overlay__ {
   sec-mst{
    compatible = "sec-mst";
    sec-mst,mst-pwr-gpio = <&gpm12 0 0>;
    sec-mst,mst-en-gpio = <&gpm14 0 0>;
    sec-mst,mst-data-gpio = <&gpm13 0 0>;
    sec-mst,mst-support-gpio = <&gpg0 1 0>;



   };
  };
 };
};
# 19 "/mnt/080b9fba-139f-40aa-b1d1-529119d8c495/develop/Android/Kernel/android_kernel_samsung_universal9610/arch/arm64/boot/dts/exynos/exynos9610-a50_common.dtsi" 2

/ {

 fragment@model {
  target-path = "/";
  __overlay__ {
   #address-cells = <2>;
   #size-cells = <1>;

   fixed-rate-clocks {
    oscclk {
     compatible = "samsung,exynos9610-oscclk";
     clock-frequency = <26000000>;
    };
   };

   secgpio_dvs {
    compatible = "samsung,exynos9610-secgpio-dvs";
    status = "okay";
   };

   sec_abc {
    compatible = "samsung,sec_abc";
    status = "okay";

    gpu {
     gpu,label="GPU fault";
     gpu,threshold_count=<20>;
     gpu,threshold_time=<1200>;
    };
    aicl {
     aicl,label="battery aicl";
     aicl,threshold_count=<5>;
     aicl,threshold_time=<300>;
    };
   };

   abc_hub {
    compatible = "samsung,abc_hub";
    status = "okay";

    bootc {
     bootc,time_spec_user = <100000>;
     bootc,time_spec_eng = <100000>;
     bootc,time_spec_fac = <100000>;
    };
   };

   speedy@11a10000 {
    #address-cells = <1>;
    #size-cells = <0>;
    status = "okay";
    s2mpu09mfd@00 {
     compatible = "samsung,s2mpu09mfd";
     acpm-ipc-channel = <2>;
     i2c-speedy-address;
     s2mpu09,wakeup = "enabled";
     s2mpu09,irq-gpio = <&gpa2 0 0>;
     reg = <0x00>;
     interrupts = <2 0 0>;
     interrupt-parent = <&gpa2>;
     pinctrl-names = "default";
     pinctrl-0 = <&pmic_irq &pm_wrsti>;

     wtsr_en = "enabled";
     smpl_en = "enabled";
     wtsr_timer_val = <3>;
     smpl_timer_val = <0>;
     check_jigon = <0>;

     init_time,sec = <0>;
     init_time,min = <0>;
     init_time,hour = <12>;
     init_time,mday = <1>;
     init_time,mon = <0>;
     init_time,year = <119>;
     init_time,wday = <2>;

     regulators {
      b1_reg: BUCK1 {
       regulator-name = "vdd_mif";
       regulator-min-microvolt = <500000>;
       regulator-max-microvolt = <1100000>;
       regulator-always-on;
       regulator-ramp-delay = <12000>;
       regulator-initial-mode = <2>;
      };

      b2_reg: BUCK2 {
       regulator-name = "vdd_cpucl1";
       regulator-min-microvolt = <500000>;
       regulator-max-microvolt = <1300000>;
       regulator-always-on;
       regulator-ramp-delay = <12000>;
       regulator-initial-mode = <1>;
      };

      b3_reg: BUCK3 {
       regulator-name = "vdd_cpucl0";
       regulator-min-microvolt = <500000>;
       regulator-max-microvolt = <1300000>;
       regulator-always-on;
       regulator-ramp-delay = <12000>;
       regulator-initial-mode = <1>;
      };

      b4_reg: BUCK4{
       regulator-name = "vdd_int";
       regulator-min-microvolt = <500000>;
       regulator-max-microvolt = <1100000>;
       regulator-always-on;
       regulator-ramp-delay = <12000>;
       regulator-initial-mode = <2>;
      };

      b5_reg: BUCK5 {
       regulator-name = "vdd_g3d";
       regulator-min-microvolt = <500000>;
       regulator-max-microvolt = <1200000>;
       regulator-always-on;
       regulator-ramp-delay = <12000>;
       regulator-initial-mode = <2>;
      };

      b6_reg: BUCK6 {
       regulator-name = "vdd_cam_vipx";
       regulator-min-microvolt = <500000>;
       regulator-max-microvolt = <1300000>;
       regulator-always-on;
       regulator-ramp-delay = <12000>;
       regulator-initial-mode = <2>;
      };

      b7_reg: BUCK7 {
       regulator-name = "vdd2_mem";
       regulator-min-microvolt = <500000>;
       regulator-max-microvolt = <1300000>;
       regulator-always-on;
       regulator-ramp-delay = <12000>;
       regulator-initial-mode = <3>;
      };

      b8_reg: BUCK8 {
       regulator-name = "vdd_lldo";
       regulator-min-microvolt = <1200000>;
       regulator-max-microvolt = <1500000>;
       regulator-always-on;
       regulator-ramp-delay = <12000>;
       regulator-initial-mode = <3>;
      };

      b9_reg: BUCK9 {
       regulator-name = "vdd_mldo";
       regulator-min-microvolt = <1800000>;
       regulator-max-microvolt = <2100000>;
       regulator-always-on;
       regulator-ramp-delay = <12000>;
       regulator-initial-mode = <3>;
      };

      l1_reg: LDO1 {
       regulator-name = "vdd_ldo1";
       regulator-min-microvolt = <700000>;
       regulator-max-microvolt = <1300000>;
       regulator-always-on;
       regulator-ramp-delay = <12000>;
       regulator-initial-mode = <3>;
      };

      l2_reg: LDO2 {
       regulator-name = "vqmmc";
       regulator-min-microvolt = <1800000>;
       regulator-max-microvolt = <3375000>;
       regulator-ramp-delay = <12000>;
      };

      l3_reg: LDO3 {
       regulator-name = "vdd_ldo3";
       regulator-min-microvolt = <800000>;
       regulator-max-microvolt = <1950000>;
       regulator-always-on;
       regulator-ramp-delay = <12000>;
       regulator-initial-mode = <3>;
      };

      l4_reg: LDO4 {
       regulator-name = "vdd_ldo4";
       regulator-min-microvolt = <500000>;
       regulator-max-microvolt = <1100000>;
       regulator-always-on;
       regulator-ramp-delay = <12000>;
       regulator-initial-mode = <1>;
      };

      l5_reg: LDO5 {
       regulator-name = "vdd_ldo5";
       regulator-min-microvolt = <800000>;
       regulator-max-microvolt = <1300000>;
       regulator-always-on;
       regulator-ramp-delay = <12000>;
       regulator-initial-mode = <1>;
      };

      l6_reg: LDO6 {
       regulator-name = "vdd_ldo6";
       regulator-min-microvolt = <800000>;
       regulator-max-microvolt = <1300000>;
       regulator-always-on;
       regulator-ramp-delay = <12000>;
       regulator-initial-mode = <1>;
      };

      l7_reg: LDO7 {
       regulator-name = "vdd_ldo7";
       regulator-min-microvolt = <800000>;
       regulator-max-microvolt = <1950000>;
       regulator-always-on;
       regulator-ramp-delay = <12000>;
       regulator-initial-mode = <1>;
      };

      l8_reg: LDO8 {
       regulator-name = "vdd_ldo8";
       regulator-min-microvolt = <500000>;
       regulator-max-microvolt = <1300000>;
       regulator-always-on;
       regulator-ramp-delay = <12000>;
       regulator-initial-mode = <1>;
      };

      l9_reg: LDO9 {
       regulator-name = "vdd_ldo9";
       regulator-min-microvolt = <500000>;
       regulator-max-microvolt = <1300000>;
       regulator-always-on;
       regulator-ramp-delay = <12000>;
       regulator-initial-mode = <1>;
      };

      l10_reg: LDO10 {
       regulator-name = "vdd_ldo10";
       regulator-min-microvolt = <500000>;
       regulator-max-microvolt = <1300000>;
       regulator-always-on;
       regulator-ramp-delay = <12000>;
       regulator-initial-mode = <1>;
      };

      l11_reg: LDO11 {
       regulator-name = "vdd_ldo11";
       regulator-min-microvolt = <500000>;
       regulator-max-microvolt = <1300000>;
       regulator-always-on;
       regulator-ramp-delay = <12000>;
       regulator-initial-mode = <3>;
      };

      l12_reg: LDO12 {
       regulator-name = "vdd_ldo12";
       regulator-min-microvolt = <800000>;
       regulator-max-microvolt = <1300000>;
       regulator-ramp-delay = <12000>;
       regulator-initial-mode = <3>;
      };

      l13_reg: LDO13 {
       regulator-name = "vdd_ldo13";
       regulator-min-microvolt = <800000>;
       regulator-max-microvolt = <1950000>;
       regulator-ramp-delay = <12000>;
       regulator-initial-mode = <3>;
      };

      l14_reg: LDO14 {
       regulator-name = "vdd_ldo14";
       regulator-min-microvolt = <1800000>;
       regulator-max-microvolt = <3375000>;
       regulator-ramp-delay = <12000>;
       regulator-initial-mode = <3>;
      };

      l33_reg: LDO33 {
       regulator-name = "vdd_ldo33";
       regulator-min-microvolt = <800000>;
       regulator-max-microvolt = <1950000>;
       regulator-ramp-delay = <12000>;
      };

      l34_reg: LDO34 {
       regulator-name = "vdd_ldo34";
       regulator-min-microvolt = <1800000>;
       regulator-max-microvolt = <3375000>;
       regulator-ramp-delay = <12000>;
      };

      l35_reg: LDO35 {
       regulator-name = "vmmc";
       regulator-min-microvolt = <1800000>;
       regulator-max-microvolt = <3375000>;
       regulator-ramp-delay = <12000>;
      };

      l36_reg: LDO36 {
       regulator-name = "vdd_ldo36";
       regulator-min-microvolt = <500000>;
       regulator-max-microvolt = <1300000>;
       regulator-always-on;
       regulator-ramp-delay = <12000>;
       regulator-initial-mode = <1>;
      };

      l37_reg: LDO37 {
       regulator-name = "vdd_ldo37";
       regulator-min-microvolt = <2800000>;
       regulator-max-microvolt = <2800000>;
       regulator-ramp-delay = <12000>;
      };

      l38_reg: LDO38 {
       regulator-name = "VDD_BTP_3P3";
       regulator-min-microvolt = <3300000>;
       regulator-max-microvolt = <3300000>;
       regulator-ramp-delay = <12000>;
      };

      l39_reg: LDO39 {
       regulator-name = "vdd_ldo39";
       regulator-min-microvolt = <1800000>;
       regulator-max-microvolt = <1800000>;
       regulator-initial-mode = <3>;
      };

      l40_reg: LDO40 {
       regulator-name = "vdd_ldo40";
       regulator-min-microvolt = <3300000>;
       regulator-max-microvolt = <3300000>;
       regulator-initial-mode = <3>;
       regulator-always-on;
      };

      l41_reg: LDO41 {
       regulator-name = "vdd_ldo41";
       regulator-min-microvolt = <1800000>;
       regulator-max-microvolt = <3375000>;
       regulator-ramp-delay = <12000>;
      };

      l42_reg: LDO42 {
       regulator-name = "vdd_ldo42";
       regulator-min-microvolt = <1800000>;
       regulator-max-microvolt = <1800000>;
       regulator-ramp-delay = <12000>;
       regulator-initial-mode = <3>;
       regulator-always-on;
      };

      l43_reg: LDO43 {
       regulator-name = "vdd_ldo43";
       regulator-min-microvolt = <500000>;
       regulator-max-microvolt = <1300000>;
       regulator-always-on;
       regulator-ramp-delay = <12000>;
       regulator-initial-mode = <1>;
      };

      l44_reg: LDO44 {
       regulator-name = "vdd_ldo44";
       regulator-min-microvolt = <800000>;
       regulator-max-microvolt = <1300000>;
       regulator-ramp-delay = <12000>;
      };
     };
    };
   };

   sec_thermistor@0 {
    compatible = "samsung,sec-thermistor";
    status = "okay";
    thermistor_name = "sec-ap-thermistor";
    id = <0>;

    adc_array = <275 324 380 450 528 619 729 856 1003 1161
       1345 1545 1766 1980 2222 2457 2685 2901 3102 3279
       3426 3551 3659>;
    temp_array = <900 850 800 750 700 650 600 550 500 450
       400 350 300 250 200 150 100 50 0 (-50)
       (-100) (-150) (-200)>;

    io-channels = <&exynos_adc 0>;
    io-channel-names = "adc-ap-temp";
    io-channel-ranges;
   };

   sec_thermistor@6 {
    compatible = "samsung,sec-thermistor";
    status = "okay";
    thermistor_name = "sec-wf-thermistor";
    id = <1>;

    adc_array = <275 324 380 450 528 619 729 856 1003 1161
       1345 1545 1766 1980 2222 2457 2685 2901 3102 3279
       3426 3551 3659>;
    temp_array = <900 850 800 750 700 650 600 550 500 450
       400 350 300 250 200 150 100 50 0 (-50)
       (-100) (-150) (-200)>;

    io-channels = <&exynos_adc 6>;
    io-channel-names = "adc-wf-temp";
    io-channel-ranges;
   };

   exynos_rgt {
    compatible = "samsung,exynos-rgt";
   };

   mailbox_cp: mcu_ipc@11920000 {
    compatible = "samsung,exynos-shd-ipc-mailbox";
    reg = <0x0 0x11920000 0x180>;
    mcu,name = "mcu_ipc_cp";
    mcu,id = <0>;
    interrupts = <0 40 0 >;
    mcu,irq_affinity_mask = <3>;
   };

   mif_pdata {


    gpios = <&gpg3 3 0>, <&gpg3 4 0>, <&gpg3 5 0>;
    pinctrl-names = "default";
   };

   mailbox_gnss: mcu_ipc@11A00000 {
    compatible = "samsung,exynos-shd-ipc-mailbox";
    reg = <0x0 0x11A00000 0x180>;
    mcu,name = "mcu_ipc_gnss";
    mcu,id = <1>;
    interrupts = <0 43 0>;
   };

   gnss_pdata {
    status = "okay";

    compatible = "samsung,gnss_shdmem_if";
    shmem,name = "KEPLER";
    shmem,device_node_name = "gnss_ipc";


    interrupts = <0 27 0>, <0 81 0>, <0 80 0>, <0 79 0>;
    interrupt-names = "ACTIVE", "WATCHDOG", "WAKEUP", "REQ_INIT";

    memory-region = <&gnss_reserved>;
    mbox_info = <&mailbox_gnss>;

    mbx,int_ap2gnss_bcmd = <0>;
    mbx,int_ap2gnss_req_fault_info = <1>;
    mbx,int_ap2gnss_ipc_msg = <2>;
    mbx,int_ap2gnss_ack_wake_set = <3>;
    mbx,int_ap2gnss_ack_wake_clr = <4>;

    mbx,irq_gnss2ap_bcmd = <0>;
    mbx,irq_gnss2ap_rsp_fault_info = <1>;
    mbx,irq_gnss2ap_ipc_msg = <2>;
    mbx,irq_gnss2ap_req_wake_clr = <4>;

    mbx,reg_bcmd_ctrl = <0>, <1>, <2>, <3>;

    reg_rx_ipc_msg = <1 5>;
    reg_tx_ipc_msg = <1 4>;
    reg_rx_head = <1 3>;
    reg_rx_tail = <1 2>;
    reg_tx_head = <1 1>;
    reg_tx_tail = <1 0>;
    fault_info = <1 0x200000 0x180000>;

    shmem,ipc_offset = <0x380000>;
    shmem,ipc_size = <0x80000>;
    shmem,ipc_reg_cnt = <32>;
   };

   gpio_keys {
    #address-cells = <1>;
    #size-cells = <0>;
    compatible = "gpio-keys";
    status = "okay";
    pinctrl-names = "default";
    pinctrl-0 = <&key_voldown &key_volup &key_power>;
    button@2 {
     label = "gpio-keys: KEY_VOLUMEDOWN";
     linux,code = <114>;
     gpios = <&gpa1 6 0xf>;
    };
    button@3 {
     label = "gpio-keys: KEY_VOLUMEUP";
     linux,code = <115>;
     gpios = <&gpa1 5 0xf>;
    };
    button@4 {
     label = "gpio-keys: KEY_POWER";
     linux,code = <116>;
     gpios = <&gpa1 7 0xf>;
     gpio-key,wakeup = <1>;
    };
   };

   tsp_ldo_en {
    compatible = "regulator-fixed";
    regulator-name = "tsp_ldo_en";
    regulator-min-microvolt = <3000000>;
    regulator-max-microvolt = <3000000>;
    gpio = <&gpg3 1 0>;
    enable-active-high;
   };

   i2c_4:i2c@13870000 {
    status = "okay";
    samsung,i2c-sda-delay = <100>;
    samsung,i2c-max-bus-freq = <400000>;
    #address-cells = <1>;
    #size-cells = <0>;
    mms_ts@48 {
     compatible = "melfas,mms_ts";
     reg = <0x48>;
     pinctrl-names = "on_state", "off_state";
     pinctrl-0 = <&attn_irq>;
     pinctrl-1 = <&attn_input>;
     melfas,vdd_en = "tsp_ldo_en";

     melfas,irq-gpio = <&gpa0 0 0>;
     melfas,scl-gpio = <&gpp1 1 0>;
     melfas,sda-gpio = <&gpp1 0 0>;
     melfas,area-size = <133 266 341>;
     melfas,max_x_y = <4095 4095>;
     melfas,node_info = <15 32 0>;
     melfas,event_info = <8 12>;
     melfas,fod_info = <15 14 27>;
     melfas,support_lpm = "true";
     melfas,fw_name = "tsp_melfas/mss100_a50.fw";
     melfas,fw_name_old = "tsp_melfas/mss100_a50_p01.fw";
     melfas,project_name = "A505";
     support_ear_detect_mode;
     enable_settings_aot;
     support_fod;
    };
   };

   usb_notifier {
    compatible = "samsung,usb-notifier";
    udc = <&udc>;
    disable_host_wakelock;
   };

   V_SYS: fixedregulator@1 {
    compatible = "regulator-fixed";
    regulator-name = "V_SYS";
    regulator-min-microvolt = <4200000>;
    regulator-max-microvolt = <4200000>;
    regulator-boot-on;
    regulator-always-on;
   };

   dwmmc2@13550000 {
    status = "okay";
    num-slots = <1>;
    supports-4bit;
    supports-cmd23;
    supports-erase;
    supports-highspeed;
    sd-uhs-sdr50;
    sd-uhs-sdr104;
    card-detect-gpio;
    bypass-for-allpass;
    card-init-hwacg-ctrl;
    skip-init-mmc-scan;
    qos-dvfs-int-level = <533000>;
    qos-dvfs-mif-level = <676000>;
    fifo-depth = <0x40>;
    desc-size = <4>;
    card-detect-delay = <200>;
    data-timeout = <200>;
    hto-timeout = <80>;
    samsung,dw-mshc-ciu-div = <3>;
    clock-frequency = <800000000>;
    ssc-rate = <3>;
    card-detect-invert;
    samsung,dw-mshc-sdr-timing = <3 0 2 0>;
    samsung,dw-mshc-ddr-timing = <3 0 2 1>;
    samsung,dw-mshc-sdr50-timing = <3 0 4 2>;
    samsung,dw-mshc-sdr104-timing = <3 0 3 0>;

    num-ref-clks = <9>;
    ciu_clkin = <25 50 50 25 50 100 200 50 50>;


    clk-drive-number = <4>;
    pinctrl-names = "default",
     "fast-slew-rate-1x",
     "fast-slew-rate-2x",
     "fast-slew-rate-3x",
     "fast-slew-rate-4x";
    pinctrl-0 = <&sd2_clk &sd2_cmd &sd2_bus1 &sd2_bus4 &dwmmc2_cd_ext_irq>;
    pinctrl-1 = <&sd2_clk_fast_slew_rate_1x>;
    pinctrl-2 = <&sd2_clk_fast_slew_rate_2x>;
    pinctrl-3 = <&sd2_clk_fast_slew_rate_3x>;
    pinctrl-4 = <&sd2_clk_fast_slew_rate_4x>;

    sec-sd-slot-type = <2>;
    #address-cells = <1>;
    #size-cells = <0>;

    slot@0 {
     reg = <0>;
     bus-width = <4>;
     disable-wp;
    };
   };

   usb_hs_tune:usb_hs_tune {
    hs_tune_cnt = <12>;


    hs_tune1 {
     tune_name = "tx_vref";
     tune_value = <0xd 0xa>;
    };

    hs_tune2 {
     tune_name = "tx_pre_emp";
     tune_value = <0x3 0x3>;
    };

    hs_tune3 {
     tune_name = "tx_pre_emp_plus";
     tune_value = <0x0 0x0>;
    };

    hs_tune4 {
     tune_name = "tx_res";
     tune_value = <0x3 0x3>;
    };

    hs_tune5 {
     tune_name = "tx_rise";
     tune_value = <0x3 0x3>;
    };

    hs_tune6 {
     tune_name = "tx_hsxv";
     tune_value = <0x3 0x3>;
    };

    hs_tune7 {
     tune_name = "tx_fsls";
     tune_value = <0x3 0x3>;
    };

    hs_tune8 {
     tune_name = "rx_sqrx";
     tune_value = <0x7 0x7>;
    };

    hs_tune9 {
     tune_name = "compdis";
     tune_value = <0x7 0x7>;
    };

    hs_tune10 {
     tune_name = "otg";
     tune_value = <0x2 0x2>;
    };

    hs_tune11 {


     tune_name = "enable_user_imp";
     tune_value = <0x0 0x0>;
    };

    hs_tune12 {

     tune_name = "is_phyclock";
     tune_value = <0x1 0x1>;
    };
   };


   ufs-srpmb {
    compatible = "samsung,ufs-srpmb";
    interrupts = <0 460 0>;
   };

   usb3_ss_tune:usb3_ss_tune {
    ss_tune_cnt = <15>;


    ss_tune1 {
     tune_name = "tx0_term_offset";
     tune_value = <0x0 0x0>;
    };

    ss_tune2 {
     tune_name = "pcs_tx_swing_full";
     tune_value = <0x7f 0x7f>;
    };

    ss_tune3 {
     tune_name = "pcs_tx_deemph_6db";
     tune_value = <0x1c 0x1c>;
    };

    ss_tune4 {
     tune_name = "pcs_tx_deemph_3p5db";
     tune_value = <0x1c 0x1c>;
    };

    ss_tune5 {
     tune_name = "tx_vboost_lvl_sstx";
     tune_value = <0x7 0x7>;
    };

    ss_tune6 {
     tune_name = "tx_vboost_lvl";
     tune_value = <0x4 0x4>;
    };

    ss_tune7 {
     tune_name = "los_level";
     tune_value = <0x9 0x9>;
    };

    ss_tune8 {
     tune_name = "los_bias";
     tune_value = <0x5 0x5>;
    };

    ss_tune9 {
     tune_name = "pcs_rx_los_mask_val";
     tune_value = <0x104 0x104>;
    };

    ss_tune10 {
     tune_name = "tx_eye_height_cntl_en";
     tune_value = <0x1 0x1>;
    };

    ss_tune11 {
     tune_name = "pipe_tx_deemph_update_delay";
     tune_value = <0x2 0x2>;
    };

    ss_tune12 {
     tune_name = "pcs_tx_swing_full_sstx";
     tune_value = <0x7f 0x7f>;
    };
    ss_tune13 {
     tune_name = "rx_eq_fix_val";
     tune_value = <0x2 0x2>;
    };

    ss_tune14 {
     tune_name = "rx_decode_mode";
     tune_value = <0x1 0x1>;
    };

    ss_tune15 {
     tune_name = "decrese_ss_tx_imp";
     tune_value = <0x1 0x1>;
    };
   };

   usb3_hs_tune:usb3_hs_tune {
    hs_tune_cnt = <10>;


    hs_tune1 {
     tune_name = "tx_pre_emp";
     tune_value = <0x3 0x3>;
    };

    hs_tune2 {
     tune_name = "tx_pre_emp_plus";
     tune_value = <0x0 0x0>;
    };

    hs_tune3 {
     tune_name = "tx_vref";
     tune_value = <0x7 0x7>;
    };

    hs_tune4 {
     tune_name = "rx_sqrx";
     tune_value = <0x7 0x7>;
    };

    hs_tune5 {
     tune_name = "tx_rise";
     tune_value = <0x3 0x3>;
    };

    hs_tune6 {
     tune_name = "compdis";
     tune_value = <0x7 0x7>;
    };

    hs_tune7 {
     tune_name = "tx_hsxv";
     tune_value = <0x3 0x3>;
    };

    hs_tune8 {
     tune_name = "tx_fsls";
     tune_value = <0x3 0x3>;
    };

    hs_tune9 {
     tune_name = "tx_res";
     tune_value = <0x3 0x3>;
    };

    hs_tune10 {
     tune_name = "utim_clk";
     tune_value = <0x1 0x1>;
    };
   };

   hall {
    status = "okay";
    compatible = "hall";
    pinctrl-names = "default";
    pinctrl-0 = <&hall_irq>;
    hall,gpio_flip_cover = <&gpa0 3 0>;
   };

   certify_hall {
    status = "okay";
    compatible = "certify_hall";
    pinctrl-names = "default";
    pinctrl-0 = <&certify_hall_irq>;
    certify_hall,gpio_certify_cover = <&gpa0 2 0>;
   };

   nad_balancer {
    compatible = "samsung,sec_nad_balancer";
    status = "okay";

    nad_balancer,timeout = <400>;

    qos {
     cl0 {
      qos,label="LIT";
      qos,delay_time=<10>;
      qos,table_size=<13>;
      qos,table=<1742000 1638000 1534000 1456000 1326000 1222000 1118000 1053000 910000
        806000 702000 598000 403000>;
     };

     cl1 {
      qos,label="BIG";
      qos,delay_time=<10>;
      qos,table_size=<15>;
      qos,table=<2314000 2210000 2184000 2080000 1976000 1898000 1768000 1664000 1508000
        1456000 1352000 1248000 1144000 1040000 936000>;
     };

     mif {
      qos,label="MIF";
      qos,delay_time=<10>;
      qos,table_size=<10>;
      qos,table=<2093000 2002000 1794000 1539000 13352000 1014000 845000 676000 546000 419000>;
     };
    };

    sleep {

     sleep,suspend_threshold = <1000>;
     sleep,resume_threshold = <1000>;
    };
   };

   argos {
    compatible = "samsung,argos";
    #address-cells = <1>;
# 935 "/mnt/080b9fba-139f-40aa-b1d1-529119d8c495/develop/Android/Kernel/android_kernel_samsung_universal9610/arch/arm64/boot/dts/exynos/exynos9610-a50_common.dtsi"
    boot_device@1 {
     net_boost,label="IPC";
     net_boost,node="rmnet0 rmnet1 rmnet2 rmnet3 rmnet4 rmnet5 rmnet6 rmnet7 umts_dm0";
     net_boost,table_size = <4>;
     net_boost,table= <
      50 0 0 910000 0 845000 0 0 0 0
      100 0 0 1326000 0 1014000 0 0 0 0
      200 0 0 1534000 0 1352000 0 0 0 0
      300 16640000 0 1456000 0 1539000 0 0 0 0
      >;
    };

    boot_device@2 {
     net_boost,label="CLAT";
     net_boost,node="clat clat4 v4-rmnet0 v4-rmnet1 v4-rmnet2 v4-rmnet3 v4-rmnet4 v4-rmnet5 v4-rmnet6 v4-rmnet7";
     net_boost,table_size = <3>;
     net_boost,table= <
      100 1040000 0 0 0 0 0 1014000 0 0 0 0
      150 1248000 0 0 0 0 0 1352000 0 0 0 0
      200 1456000 0 0 0 0 0 2093000 0 0 0 0
      >;
    };

    boot_device@3 {
     net_boost,label="USB";
     net_boost,node="rndis0";
     net_boost,table_size = <1>;
     net_boost,table= < 0 0 0 0 0 0 0 0 1 0 >;
    };
   };

   i2c@20 {
    compatible = "i2c-gpio";
    gpios = <&gpp1 2 0
      &gpp1 3 0>;
    i2c-gpio,delay-us = <5>;
    pinctrl-names = "default","on_i2c","off_i2c";
    pinctrl-0 = <&grip_i2c>;
    pinctrl-1 = <&grip_i2c>;
    pinctrl-2 = <&grip_gpio>;

    tc3xxk@20 {
     compatible = "coreriver,tc3xx-grip";
     pinctrl-names = "default";
     pinctrl-0 = <&grip_int &grip_ldo>;
     reg = <0x20>;
     interrupt-parent = <&gpa2>;
     interrupts = <7 0 0>;
     coreriver,scl-gpio = <&gpp1 3 0>;
     coreriver,sda-gpio = <&gpp1 2 0>;
     coreriver,irq-gpio = <&gpa2 7 0>;
     coreriver,ldo_en = <&gpg2 1 0>;
     coreriver,i2c-gpio = "true";
     coreriver,boot-on-ldo = "true";
     coreriver,fw_name = "coreriver/tc305k_a50ser.fw";
     coreriver,use_bitmap = <1>;
    };
   };

   fpcb_type {
    compatible = "fpcb_type";
    gpios = <&gpg2 5 0
      &gpg2 6 0>;
    status = "okay";
   };
  };
 };
};

&udc {
 status = "okay";
 dwc3 {
  dr_mode = "otg";
  maximum-speed = "high-speed";
 };
};

&usbdrd_dwc3 {
 dr_mode = "otg";
 maximum-speed = "high-speed";




 ldo-names = "vdd_ldo12", "vdd_ldo13", "vdd_ldo14";
};

&usbdrd_phy {
 status = "okay";
 usb3phy-isolation = <1>;
 hs_tune_param = <&usb_hs_tune>;
};

&usbdrd3_phy {
 status = "okay";
 usb3phy-isolation = <1>;
 hs_tune_param = <&usb3_hs_tune>;
 ss_tune_param = <&usb3_ss_tune>;
};

&serial_0 {
 samsung,uart-logging;
 status = "okay";
};

&pinctrl_0 {
 key_voldown: key-voldown {
  samsung,pins = "gpa1-6";
  samsung,pin-function = <0xf>;
  samsung,pin-pud = <0>;
  samsung,pin-drv = <0>;
 };

 key_volup: key-volup {
  samsung,pins = "gpa1-5";
  samsung,pin-function = <0xf>;
  samsung,pin-pud = <0>;
  samsung,pin-drv = <0>;
 };

 key_power: key-power {
  samsung,pins = "gpa1-7";
  samsung,pin-function = <0xf>;
  samsung,pin-pud = <0>;
  samsung,pin-drv = <0>;
 };

 attn_irq: attn-irq {
  samsung,pins = "gpa0-0";
  samsung,pin-function = <0xf>;
  samsung,pin-pud = <0>;
  samsung,pin-drv = <0>;
 };

 attn_input: attn-input {
  samsung,pins = "gpa0-0";
  samsung,pin-function = <0>;
  samsung,pin-pud = <1>;
 };

 if_pmic_irq: if-pmic-irq {
  samsung,pins = "gpa2-2";
  samsung,pin-function = <0>;
  samsung,pin-pud = <0>;
  samsung,pin-drv = <0>;
 };

 pmic_irq: pmic-irq {
  samsung,pins = "gpa2-0";
  samsung,pin-pud = <3>;
  samsung,pin-drv = <3>;
 };

 codec_irq: codec_irq {
  samsung,pins ="gpa1-2";
  samsung,pin-function = <0xf>;
  samsung,pin-pud = <0>;
 };

 hall_irq: hall-irq {
  samsung,pins = "gpa0-3";
  samsung,pin-function = <0xf>;
  samsung,pin-pud = <0>;
  samsung,pin-drv = <0>;
 };

 certify_hall_irq: certify-hall-irq {
  samsung,pins = "gpa0-2";
  samsung,pin-function = <0xf>;
  samsung,pin-pud = <0>;
  samsung,pin-drv = <0>;
 };

 usbpd_irq: usbpd-irq {
  samsung,pins = "gpa2-3";
  samsung,pin-function = <0x0f>;
  samsung,pin-pud = <0>;
  samsung,pin-drv = <0>;
 };
};

&pinctrl_4 {
# 1131 "/mnt/080b9fba-139f-40aa-b1d1-529119d8c495/develop/Android/Kernel/android_kernel_samsung_universal9610/arch/arm64/boot/dts/exynos/exynos9610-a50_common.dtsi"
 vbus_discharging: vbus-discharging {
  samsung,pins = "gpg0-4";
  samsung,pin-function = <1>;
  samsung,pin-pud = <0>;
  samsung,pin-drv = <0>;
  samsung,pin-val = <0>;
  samsung,pin-con-pdn = <3>;
  samsung,pin-pud-pdn = <0>;
 };


 pm_wrsti: pm-wrsti {
  samsung,pins = "gpg0-7";
  samsung,pin-con-pdn = <3>;
 };

 grip_ldo: grip-ldo {
  samsung,pins = "gpg2-1";
  samsung,pin-function = <1>;
  samsung,pin-pud = <0>;
 };
};

&fmp_0 {
  exynos,block-type = "sda";
  exynos,fips-block_offset = <5>;
};


&usi_0_shub {
 status = "disabled";
};


&usi_0_shub_i2c {

 status = "disabled";
};


&usi_0_cmgp {

 usi_v2_mode = "spi";
 status = "okay";
};


&usi_0_cmgp_i2c {

 status = "disabled";
};


&usi_1_cmgp {

 status = "disabled";
};


&usi_1_cmgp_i2c {
 usi_v2_mode = "i2c";
 status = "okay";
};


&usi_2_cmgp {

 usi_v2_mode = "i2c";
 status = "okay";
};


&usi_2_cmgp_i2c {

 status = "disabled";
};


&usi_3_cmgp {
 usi_v2_mode = "i2c";
 status = "okay";
};


&usi_3_cmgp_i2c {

 status = "disabled";
};


&usi_4_cmgp {
 usi_v2_mode = "spi";
 status = "okay";
};


&usi_4_cmgp_i2c {
 status = "disabled";
};


&usi_peri_usi_0 {
 usi_v2_mode = "i2c";
 status = "okay";
};


&usi_peri_usi_0_i2c {

 status = "disabled";
};


&usi_peri_spi_1 {
 usi_v2_mode = "spi";
 status = "okay";
};

&i2c_0 {
 i2c-gpio,delay-us = <5>;
 status = "okay";
 #address-cells = <1>;
 #size-cells = <0>;
 samsung,i2c-max-bus-freq = <400000>;
 usbpd-5713@33 {
  compatible = "sm5713-usbpd,i2c";
  reg = <0x33>;
  pinctrl-names = "default";

  support_pd_role_swap;
  pinctrl-0 = <&usbpd_irq &vbus_discharging>;
  usbpd,usbpd_int = <&gpa2 3 0>;
  usbpd,vbus_discharging = <&gpg0 4 0>;
 };
};

&i2c_1 {
 #address-cells = <1>;
 #size-cells = <0>;
 status = "okay";
 samsung,i2c-max-bus-freq = <400000>;
 sm5713@49{
  compatible = "siliconmitus,sm5713mfd";
  reg = <0x49>;
  pinctrl-names = "default";
  pinctrl-0 = <&chg_en &if_pmic_irq>;
  sm5713,irq-gpio = <&gpa2 2 0>;
  sm5713,wakeup;
 };
};

&i2c_3 {
 status = "okay";
 #address-cells = <1>;
 #size-cells = <0>;
 s2mpb03@56 {
  compatible = "samsung,s2mpb03pmic";
  reg = <0x56>;

  s2mpb03,wakeup;

  regulators {
   __ldo1_reg: s2mpb03-ldo1 {
    regulator-name = "RCAM1_DVDD_1P05";
    regulator-min-microvolt = <1050000>;
    regulator-max-microvolt = <1050000>;
   };

   __ldo2_reg: s2mpb03-ldo2 {
    regulator-name = "FCAM_DVDD_1P05";
    regulator-min-microvolt = <1050000>;
    regulator-max-microvolt = <1050000>;
   };

   __ldo3_reg: s2mpb03-ldo3 {
    regulator-name = "CAM_VDDIO_1P8";
    regulator-min-microvolt = <1800000>;
    regulator-max-microvolt = <1800000>;
   };

   __ldo4_reg: s2mpb03-ldo4 {
    regulator-name = "RCAM3_DVDD_1P2";
    regulator-min-microvolt = <1200000>;
    regulator-max-microvolt = <1200000>;
   };

   __ldo5_reg: s2mpb03-ldo5 {
    regulator-name = "RCAM2_AVDD_2P8";
    regulator-min-microvolt = <2800000>;
    regulator-max-microvolt = <2800000>;
   };

   __ldo6_reg: s2mpb03-ldo6 {
    regulator-name = "RCAM1_AVDD_2P8";
    regulator-min-microvolt = <2800000>;
    regulator-max-microvolt = <2800000>;
   };

   __ldo7_reg: s2mpb03-ldo7 {
    regulator-name = "FCAM_AVDD_2P8";
    regulator-min-microvolt = <2800000>;
    regulator-max-microvolt = <2800000>;
   };
  };
 };
};
# 15 "/mnt/080b9fba-139f-40aa-b1d1-529119d8c495/develop/Android/Kernel/android_kernel_samsung_universal9610/arch/arm64/boot/dts/exynos/exynos9610-a50_swa_open_06.dts" 2
# 1 "/mnt/080b9fba-139f-40aa-b1d1-529119d8c495/develop/Android/Kernel/android_kernel_samsung_universal9610/arch/arm64/boot/dts/exynos/battery_data_a50_cis_ser_02.dtsi" 1
# 12 "/mnt/080b9fba-139f-40aa-b1d1-529119d8c495/develop/Android/Kernel/android_kernel_samsung_universal9610/arch/arm64/boot/dts/exynos/battery_data_a50_cis_ser_02.dtsi"
# 1 "/mnt/080b9fba-139f-40aa-b1d1-529119d8c495/develop/Android/Kernel/android_kernel_samsung_universal9610/arch/arm64/boot/dts/exynos/battery_data_a50_common.dtsi" 1
# 12 "/mnt/080b9fba-139f-40aa-b1d1-529119d8c495/develop/Android/Kernel/android_kernel_samsung_universal9610/arch/arm64/boot/dts/exynos/battery_data_a50_common.dtsi"
/ {
 fragment@battery {
  target-path = "/";
  __overlay__ {
   sm5713-fuelgauge {
    status = "okay";
    fuelgauge,fuel_alert_soc = <1>;
    fuelgauge,capacity_max = <1000>;
    fuelgauge,capacity_max_margin = <300>;
    fuelgauge,capacity_min = <0>;
    fuelgauge,capacity_calculation_type = <0x1F>;
    fuelgauge,using_temp_compensation;
    fuelgauge,low_temp_limit = <100>;
    fuelgauge,using_hw_vempty;
    fuelgauge,sw_v_empty_voltage = <3200>;
    fuelgauge,sw_v_empty_voltage_cisd = <3100>;
    fuelgauge,sw_v_empty_recover_voltage = <3480>;
    battery_params {
     battery,id = <0>;
     battery0,battery_type = <4400 0x0 0x1D44>;
     battery0,battery_table0 = <
      0x1400 0x1B33 0x1BAF 0x1CDD 0x1D5D 0x1D82 0x1D8A 0x1D9D
      0x1DDF 0x1E2C 0x1E50 0x1E7D 0x1EBF 0x1F0B 0x1F4F 0x1F9B
      0x1FBB 0x1FCB 0x1FF5 0x2093 0x20AE 0x20E2 0x224B 0x2400
      >;
     battery0,battery_table1 = <
      0x0000 0x0098 0x00F5 0x034C 0x04E6 0x0799 0x0A4C 0x0D00
      0x124C 0x1D19 0x2519 0x2D33 0x354C 0x3A99 0x3D4C 0x42B3
      0x4566 0x4819 0x4AB3 0x5019 0x52CC 0x5580 0x6400 0x6419
      >;
     battery0,battery_table2 = <
      0x4B 0x44 0x40 0x3E 0x3C 0x3B 0x38 0x37
      0x35 0x34 0x34 0x33 0x33 0x33 0x33 0x32
      >;
     battery0,rce_value = <0x04E1 0x03E6 0x01D7>;
     battery0,rs_value = <0x00a4 0x147 0x146 0x3800 0x007a>;
     battery0,misc = <0x0000>;
     battery0,topoff_soc = <0 3 400>;
     battery0,vit_period = <0x0a0a>;
     battery0,dtcd_value = <0x1>;
     battery0,volt_cal = <0x8012>;
     battery0,curr_offset = <1 0 0 0 0 0 0>;
     battery0,mix_value = <0x0103 0x0004>;
     battery0,temp_std = <25>;
     battery0,temp_cal = <0 6 1 11 (-1) 1 6 1 9 1>;
     battery0,ext_temp_cal = <0 2 1 2 1 1 2 3 2 3>;
     battery0,temp_volcal = <1 15 1>;
     battery0,temp_offset = <1 11 1 1 8 (-1)>;
     battery0,curr_cal = <0x887D 0x887D 0x887D 0x8080 0x8080 0x8080>;
     battery0,tem_poff = <3400 50 3250 50>;
     battery0,arsm = <1 3 1 0x6>;
     battery0,cycle_cfg = <0 0 0>;
     battery0,full_offset = <0 0>;
     battery0,v_offset_cancel = <0 0 100 10>;
     battery0,v_alarm = <3100 0>;
     battery0,data_ver = <3>;
     battery0,v_max_table = <0x224B 0x2220 0x21FD 0x21DB 0x2185>;
     battery0,q_max_table = <0x1D44 0x1CC4 0x1C44 0x1BC4 0x1A85>;
    };
   };

   pdic-manager {

    pdic,max_power = <5000>;
    pdic,op_power = <2500>;
    pdic,max_voltage = <6000>;
    pdic,max_current = <2000>;
    pdic,min_current = <500>;

    pdic,giveback = <0>;
    pdic,usb_com_capable = <1>;
    pdic,no_usb_suspend = <1>;


    source,max_voltage = <5000>;
    source,min_voltage = <4000>;
    source,max_power = <2500>;
   };

   battery {
    status = "okay";
    compatible = "samsung,sec-battery";

    pinctrl-names = "default";

    battery,vendor = "Battery";
    battery,charger_name = "sm5713-charger";
    battery,fuelgauge_name = "sm5713-fuelgauge";
    battery,technology = <2>;
    battery,fgsrc_switch_name = "sm5713-fuelgauge";

    battery,chip_vendor = "LSI";
    battery,temp_adc_type = <1>;

    battery,temp_check_type = <2>;
    battery,usb_temp_check_type = <0>;
    battery,chg_temp_check_type = <2>;
    battery,wpc_temp_check_type = <0>;

    battery,thermal_source = <3>;
    battery,usb_thermal_source = <0>;
    battery,chg_thermal_source = <3>;
    battery,wpc_thermal_source = <0>;

    battery,polling_time = <10 30 30 30 3600>;

    battery,temp_table_adc = <314 364 418 492 576 654 733 784 913 1043 1077 1107 1141 1175 1210 1244 1278 1312
        1346 1381 1493 1608 1808 2061 2309 2502 2636 2725 2818 2923 3112 3257 3400 3515 3612>;
    battery,temp_table_data = <900 850 800 750 700 650 620 600 550 500 490 480 470 460 450 440 430 420
        410 400 380 350 300 250 200 150 120 100 80 50 0 (-50) (-100) (-150) (-200)>;

    battery,chg_temp_table_adc = <290 339 391 461 542 631 685 735 810 883 1028 1188 1276 1338 1423 1531 1736 1982
        2224 2420 2554 2639 2728 2835 3030 3187 3326 3461 3562>;
    battery,chg_temp_table_data = <900 850 800 750 700 650 620 600 580 550 500 450 420 400 380 350 300 250
        200 150 120 100 80 50 0 (-50) (-100) (-150) (-200)>;

    battery,inbat_voltage = <1>;
    battery,inbat_voltage_table_adc = <2817 2803 2783 2753 2728 2701 2680 2654 2628 2597
        2565 2536 2509 2478 2450 2426 2401 2372 2343 2321 2290>;
    battery,inbat_voltage_table_data = <4383 4352 4306 4253 4204 4152 4101 4053 4002 3954
        3903 3852 3801 3750 3702 3654 3601 3552 3503 3456 3402>;

    battery,adc_check_count = <5>;

    battery,cable_check_type = <4>;
    battery,cable_source_type = <1>;
    battery,polling_type = <1>;
    battery,monitor_initial_count = <0>;

    battery,battery_check_type = <0>;
    battery,check_count = <0>;
    battery,check_adc_max = <1440>;
    battery,check_adc_min = <0>;

    battery,ovp_uvlo_check_type = <3>;

    battery,temp_check_count = <1>;
    battery,temp_highlimit_threshold_normal = <800>;
    battery,temp_highlimit_recovery_normal = <780>;
    battery,temp_high_threshold_normal = <500>;
    battery,temp_high_recovery_normal = <480>;
    battery,temp_low_threshold_normal = <0>;
    battery,temp_low_recovery_normal = <20>;
    battery,temp_highlimit_threshold_lpm = <800>;
    battery,temp_highlimit_recovery_lpm = <780>;
    battery,temp_high_threshold_lpm = <500>;
    battery,temp_high_recovery_lpm = <480>;
    battery,temp_low_threshold_lpm = <0>;
    battery,temp_low_recovery_lpm = <20>;
    battery,wpc_high_threshold_normal = <450>;
    battery,wpc_high_recovery_normal = <430>;
    battery,wpc_low_threshold_normal = <0>;
    battery,wpc_low_recovery_normal = <20>;

    battery,full_check_type = <2>;
    battery,full_check_type_2nd = <2>;
    battery,full_check_count = <1>;
    battery,chg_gpio_full_check = <0>;
    battery,chg_polarity_full_check = <1>;

    battery,chg_heating_prevention_method = <0>;
    battery,chg_high_temp = <500>;
    battery,chg_high_temp_recovery = <480>;
    battery,chg_input_limit_current = <1000>;
    battery,chg_charging_limit_current = <1700>;

    battery,wpc_temp_control_source = <0>;
    battery,wpc_high_temp = <380>;
    battery,wpc_high_temp_recovery = <360>;
    battery,wpc_charging_limit_current = <600>;
    battery,wpc_temp_lcd_on_control_source = <0>;
    battery,wpc_lcd_on_high_temp = <380>;
    battery,wpc_lcd_on_high_temp_rec = <360>;
    battery,wpc_lcd_on_charging_limit_current = <450>;

    battery,wpc_store_high_temp = <360>;
    battery,wpc_store_high_temp_recovery = <340>;
    battery,wpc_store_lcd_on_high_temp = <360>;
    battery,wpc_store_lcd_on_high_temp_rec = <300>;
    battery,wpc_store_lcd_on_charging_limit_current = <400>;

    battery,sleep_mode_limit_current = <500>;
    battery,wc_full_input_limit_current = <100>;

    battery,mix_high_temp = <420>;
    battery,mix_high_chg_temp = <500>;
    battery,mix_high_temp_recovery = <390>;




    battery,full_condition_type = <13>;
    battery,full_condition_soc = <93>;
    battery,full_condition_vcell = <4250>;

    battery,recharge_check_count = <1>;
    battery,recharge_condition_type = <4>;
    battery,recharge_condition_soc = <98>;
    battery,recharge_condition_vcell = <4280>;

    battery,charging_total_time = <14400>;
    battery,hv_charging_total_time = <10800>;
    battery,normal_charging_total_time = <18000>;
    battery,usb_charging_total_time = <36000>;
    battery,recharging_total_time = <5400>;
    battery,charging_reset_time = <0>;

    battery,chg_float_voltage = <4350>;

    battery,swelling_high_temp_block = <410>;
    battery,swelling_high_temp_recov = <390>;
    battery,swelling_low_temp_block_1st = <150>;
    battery,swelling_low_temp_recov_1st = <170>;
    battery,swelling_low_temp_block_2nd = <50>;
    battery,swelling_low_temp_recov_2nd = <70>;

    battery,swelling_low_temp_current = <900>;
    battery,swelling_low_temp_current_2nd = <350>;
    battery,swelling_low_temp_topoff = <200>;
    battery,swelling_high_temp_current = <1400>;
    battery,swelling_high_temp_topoff = <200>;
    battery,swelling_wc_high_temp_current = <900>;
    battery,swelling_wc_low_temp_current = <900>;
    battery,swelling_wc_low_temp_current_2nd = <350>;

    battery,swelling_drop_float_voltage = <4150>;
    battery,swelling_high_rechg_voltage = <4000>;
    battery,swelling_low_rechg_voltage = <4000>;

    battery,siop_event_check_type = <1>;
    battery,siop_call_cv_current = <330>;
    battery,siop_call_cc_current = <330>;

    battery,siop_input_limit_current = <1200>;
    battery,siop_charging_limit_current = <1000>;
    battery,siop_hv_input_limit_current = <700>;
    battery,siop_hv_charging_limit_current = <1000>;

    battery,input_current_by_siop_20 = <1000>;

    battery,siop_wireless_input_limit_current = <600>;
    battery,siop_wireless_charging_limit_current = <700>;
    battery,siop_hv_wireless_input_limit_current = <600>;
    battery,siop_hv_wireless_charging_limit_current = <700>;
    battery,siop_store_hv_wireless_input_limit_current = <450>;

    battery,ttf_hv_charge_current = <2400>;
    battery,ttf_hv_wireless_charge_current = <1050>;
    battery,ttf_wireless_charge_current = <900>;

    battery,rp_current_rp1 = <500>;
    battery,rp_current_rp2 = <1500>;
    battery,rp_current_rp3 = <3000>;
    battery,rp_current_rdu_rp3 = <2100>;
    battery,rp_current_abnormal_rp3 = <1800>;

    battery,pd_charging_charge_power = <15000>;
    battery,max_charging_current = <2400>;
    battery,battery_full_capacity = <4000>;


    battery,age_data = <0 4350 4280 4250 93
      300 4330 4260 4230 92
      400 4310 4240 4210 91
      700 4290 4220 4190 90
      1000 4240 4170 4140 89
      >;

    battery,pre_afc_input_current = <500>;
    battery,prepare_ta_delay = <0>;

    battery,max_input_voltage = <9000>;
    battery,max_input_current = <3000>;

    battery,enable_water_resistance;

    battery,standard_curr = <2400>;
    battery,expired_time = <11400>;
    battery,recharging_expired_time = <5400>;

    battery,cisd_max_voltage_thr = <4400>;

    battery,cisd_alg_index = <7>;
    battery,ignore_cisd_index = <0 960>;
    battery,ignore_cisd_index_d = <0 120>;

    io-channels = <&exynos_adc 1>, <&exynos_adc 2>, <&exynos_adc 3>;
    io-channel-names = "adc-temp", "adc-in-bat", "adc-chg-temp";
    #io-channel-cells = <5>;
    io-channel-ranges;
   };
# 345 "/mnt/080b9fba-139f-40aa-b1d1-529119d8c495/develop/Android/Kernel/android_kernel_samsung_universal9610/arch/arm64/boot/dts/exynos/battery_data_a50_common.dtsi"
   cable-info {
    default_input_current = <1800>;
    default_charging_current = <2100>;
    full_check_current_1st = <400>;
    full_check_current_2nd = <200>;

    current_group_1 {
     cable_number = <2 19 21 22 23 30>;
     input_current = <500>;
     charging_current = <500>;
    };
    current_group_2 {
     cable_number = <25 31>;
     input_current = <1000>;
     charging_current = <1000>;
    };
    current_group_3 {
     cable_number = <5 32>;
     input_current = <1500>;
     charging_current = <1500>;
    };
    current_group_4 {
     cable_number = <6 7 8>;
     input_current = <1650>;
     charging_current = <2400>;
    };
    current_group_5 {
     cable_number = <9>;
     input_current = <1650>;
     charging_current = <2400>;
    };
    current_group_6 {
     cable_number = <10 12 15 27 33>;
     input_current = <820>;
     charging_current = <2400>;
    };
    current_group_7 {
     cable_number = <13>;
     input_current = <750>;
     charging_current = <2400>;
    };
    current_group_8 {
     cable_number = <24>;
     input_current = <1000>;
     charging_current = <450>;
    };
    current_group_9 {
     cable_number = <26>;
     input_current = <2000>;
     charging_current = <1800>;
    };
    current_group_10 {
     cable_number = <11 14 16 28 35>;
     input_current = <750>;
     charging_current = <2400>;
    };
    current_group_11 {
     cable_number = <29>;
     input_current = <500>;
     charging_current = <1400>;
    };
    current_group_12 {
     cable_number = <1 4>;
     input_current = <475>;
     charging_current = <550>;
    };
    current_group_13 {
     cable_number = <34>;
     input_current = <1200>;
     charging_current = <2850>;
    };
   };
  };
 };
};

&pinctrl_4 {
 chg_en: chg-en {
  samsung,pins = "gpg2-3";
  samsung,pin-function = <1>;
  samsung,pin-pud = <1>;
  samsung,pin-drv = <0>;
 };
};
# 13 "/mnt/080b9fba-139f-40aa-b1d1-529119d8c495/develop/Android/Kernel/android_kernel_samsung_universal9610/arch/arm64/boot/dts/exynos/battery_data_a50_cis_ser_02.dtsi" 2

/ {
};
# 16 "/mnt/080b9fba-139f-40aa-b1d1-529119d8c495/develop/Android/Kernel/android_kernel_samsung_universal9610/arch/arm64/boot/dts/exynos/exynos9610-a50_swa_open_06.dts" 2
# 1 "/mnt/080b9fba-139f-40aa-b1d1-529119d8c495/develop/Android/Kernel/android_kernel_samsung_universal9610/arch/arm64/boot/dts/exynos/exynos9610-a50_fingerprint_04.dtsi" 1
# 12 "/mnt/080b9fba-139f-40aa-b1d1-529119d8c495/develop/Android/Kernel/android_kernel_samsung_universal9610/arch/arm64/boot/dts/exynos/exynos9610-a50_fingerprint_04.dtsi"
&pinctrl_4 {
 btp_rst: btp-rst {
  samsung,pins = "gpg3-0";
  samsung,pin-function = <1>;
  samsung,pin-pud = <1>;
  samsung,pin-drv = <0>;
 };


 spi7_bus_inactive: spi7-bus-inactive {
  samsung,pins = "gpp2-4", "gpp2-5", "gpp2-7";
  samsung,pin-function = <1>;
  samsung,pin-pud = <0>;
  samsung,pin-drv = <2>;
  samsung,pin-val = <0>;
 };

 spi7_miso_inactive: spi17-miso-inactive {
  samsung,pins = "gpp2-6";
  samsung,pin-function = <0>;
  samsung,pin-pud = <1>;
  samsung,pin-drv = <2>;
 };

 spi7_clk: spi7-clk {
  samsung,pins = "gpp2-4";
  samsung,pin-function = <2>;
  samsung,pin-pud = <1>;
  samsung,pin-drv = <2>;
 };

 spi7_cs: spi7-cs {
  samsung,pins = "gpp2-7";
  samsung,pin-function = <2>;
  samsung,pin-pud = <3>;
  samsung,pin-drv = <2>;
 };

 spi7_miso: spi7-miso {
  samsung,pins = "gpp2-6";
  samsung,pin-function = <2>;
  samsung,pin-pud = <1>;
  samsung,pin-drv = <2>;
 };

 spi7_mosi: spi7-mosi {
  samsung,pins = "gpp2-5";
  samsung,pin-function = <2>;
  samsung,pin-pud = <1>;
  samsung,pin-drv = <2>;
 };
};


&spi_7 {
 status = "okay";

 dma-mode;
 dmas = <&pdma0 21 &pdma0 20>;

 etspi-spi@0 {
  compatible = "etspi,et7xx";
  reg = <0>;
  spi-max-frequency = <50000000>;
  pinctrl-names = "default", "pins_poweron", "pins_poweroff";
  pinctrl-0 = <&btp_rst>;
  pinctrl-1 = <&spi7_clk &spi7_cs &spi7_miso &spi7_mosi>;
  pinctrl-2 = <&spi7_bus_inactive &spi7_miso_inactive>;

  gpio-controller;
  #gpio-cells = <2>;

  etspi-sleepPin = <&gpg3 0 0>;
  etspi-regulator = "VDD_BTP_3P3";
  etspi-chipid = "ET713";
  etspi-position = "13.77,0.00,7.29,7.29,14.80,14.80,12.50,12.50,5.00";
  controller-data {
   cs-gpio = <&gpp2 7 0>;
   samsung,spi-feedback-delay = <0>;
   samsung,spi-chip-select-mode = <0>;
  };
 };
};
# 17 "/mnt/080b9fba-139f-40aa-b1d1-529119d8c495/develop/Android/Kernel/android_kernel_samsung_universal9610/arch/arm64/boot/dts/exynos/exynos9610-a50_swa_open_06.dts" 2
# 1 "/mnt/080b9fba-139f-40aa-b1d1-529119d8c495/develop/Android/Kernel/android_kernel_samsung_universal9610/arch/arm64/boot/dts/exynos/exynos9610-a50_sensorhub_00.dtsi" 1
# 14 "/mnt/080b9fba-139f-40aa-b1d1-529119d8c495/develop/Android/Kernel/android_kernel_samsung_universal9610/arch/arm64/boot/dts/exynos/exynos9610-a50_sensorhub_00.dtsi"
&contexthub_0 {
 os-type = "shub_exynos9610_a50.bin";

 chub-irq-pin-len = <1>;
 chub-irq-pin = <&gpm8 0 0>;
 clocks =

  <&clock ((600) + 0)>,

  <&clock ((100) + 25)>;
 clock-names =
  "chub_bus",
  "cmgp_i2c";

 sensor-ldo-en = <&gpm21 0 1>;
 mag-check-nfc = <&gpg0 3 0>;
 mag-check-mst = <&gpg0 1 0>;


 ssp-acc-position = <4>;
 ssp-mag-position = <2>;
 ssp-prox-thresh-addval = /bits/ 16 <40 20>;
 ssp-mag-array = /bits/ 8 <113 83 130 205 116 166 0 143 215
  54 81 236 191 142 253 61 255 108
  109 145 196 250 32 139 10 154 45>;
 ssp-mag-nfc-array = /bits/ 8 <174 89 195 235 77 124 1 28 210
  54 196 215 152 228 251 135 255 215
  234 100 195 254 15 145 10 218 222>;
 ssp-mag-mst-array = /bits/ 8 <12 90 72 204 107 140 0 64 205
  54 81 3 147 102 252 122 1 129
  37 83 194 0 174 29 10 117 239>;
 ssp-light-position = /bits/ 32 <51 81 2 59 1 8>;
 ssp-light-cam-lux = /bits/ 32 <100 200>;
 ssp-light-cam-br = /bits/ 32 <60 60>;
};
# 18 "/mnt/080b9fba-139f-40aa-b1d1-529119d8c495/develop/Android/Kernel/android_kernel_samsung_universal9610/arch/arm64/boot/dts/exynos/exynos9610-a50_swa_open_06.dts" 2
# 1 "/mnt/080b9fba-139f-40aa-b1d1-529119d8c495/develop/Android/Kernel/android_kernel_samsung_universal9610/arch/arm64/boot/dts/exynos/exynos9610-a50_nfc_01.dtsi" 1
# 13 "/mnt/080b9fba-139f-40aa-b1d1-529119d8c495/develop/Android/Kernel/android_kernel_samsung_universal9610/arch/arm64/boot/dts/exynos/exynos9610-a50_nfc_01.dtsi"
&pinctrl_0 {
 nfc_clk_req: nfc_clk_req {
  samsung,pins = "gpa2-6";
  samsung,pin-pud = <0>;
  };

 nfc_clk_req_nc: nfc_clk_req_nc {
  samsung,pins = "gpa2-6";
  samsung,pin-function = <0>;
  samsung,pin-pud = <1>;
  };

 xclkout1_nc: xclkout1_nc {
  samsung,pins = "gpq0-0";
  samsung,pin-function = <0>;
  samsung,pin-pud = <1>;
 };
};

&pinctrl_4 {
 nfc_firm: nfc_firm {
  samsung,pins = "gpg1-0";
  samsung,pin-function = <1>;
  samsung,pin-pud = <0>;
  samsung,pin-val = <0>;
  samsung,pin-con-pdn = <3>;
  samsung,pin-pud-pdn = <0>;
 };

 nfc_en: nfc_en {
  samsung,pins = "gpg0-0";
  samsung,pin-function = <0>;
  samsung,pin-pud = <0>;
  samsung,pin-drv = <0>;
  samsung,pin-con-pdn = <3>;
  samsung,pin-pud-pdn = <0>;
 };

 nfc_pwr_en: nfc_pwr_en {
  samsung,pins = "gpg2-0";
  samsung,pin-function = <1>;
  samsung,pin-pud = <0>;
  samsung,pin-val = <0>;
  samsung,pin-con-pdn = <3>;
  samsung,pin-pud-pdn = <0>;
 };

 nfc_check: nfc-check {
  samsung,pins = "gpg0-3";
  samsung,pin-function = <0>;
  samsung,pin-pud = <0>;
  samsung,pin-pud-pdn = <0>;
 };

 nfc_firm_nc: nfc_firm_nc {
  samsung,pins = "gpg1-0";
  samsung,pin-function = <0>;
  samsung,pin-pud = <1>;
  samsung,pin-con-pdn = <2>;
  samsung,pin-pud-pdn = <1>;
 };

 nfc_en_nc: nfc_en_nc {
  samsung,pins = "gpg0-0";
  samsung,pin-function = <0>;
  samsung,pin-pud = <1>;
  samsung,pin-con-pdn = <2>;
  samsung,pin-pud-pdn = <1>;
 };

 nfc_pwr_en_nc: nfc_pwr_en_nc {
  samsung,pins = "gpg2-0";
  samsung,pin-function = <0>;
  samsung,pin-pud = <1>;
  samsung,pin-con-pdn = <2>;
  samsung,pin-pud-pdn = <1>;
 };
};


&hsi2c_6 {
 #address-cells = <1>;
 #size-cells = <0>;
 status = "okay";
 clock-frequency = <400000>;
 samsung,reset-before-trans;

 sec-nfc@27 {
  compatible = "sec-nfc";
  reg = <0x27>;

  interrupts = <0 0 0>;
  interrupt-parent = <&gpa1>;

  sec-nfc,ven-gpio = <&gpg0 0 0>;
  sec-nfc,firm-gpio = <&gpg1 0 1>;
  sec-nfc,irq-gpio = <&gpa1 0 0>;
  sec-nfc,check_nfc = <&gpg0 3 0>;
  sec-nfc,clk_req-gpio = <&gpa2 6 0>;
  sec-nfc,clk_use = <2>;
  sec-nfc,pvdd_en = <&gpg2 0 0>;

  clocks = <&clock ((800) + 0)>;
  clock-names = "oscclk_nfc";
  sec-nfc,nfc_ap_clk;

  pinctrl-names = "default", "nfc_nc";
  pinctrl-0 = <&nfc_en &nfc_firm &nfc_pwr_en &xclkout1 &nfc_clk_req &nfc_check>;
  pinctrl-1 = <&nfc_en_nc &nfc_firm_nc &nfc_pwr_en_nc &nfc_clk_req_nc &xclkout1_nc>;
 };
};
# 19 "/mnt/080b9fba-139f-40aa-b1d1-529119d8c495/develop/Android/Kernel/android_kernel_samsung_universal9610/arch/arm64/boot/dts/exynos/exynos9610-a50_swa_open_06.dts" 2
# 1 "/mnt/080b9fba-139f-40aa-b1d1-529119d8c495/develop/Android/Kernel/android_kernel_samsung_universal9610/arch/arm64/boot/dts/exynos/exynos9610-a50_swa_open_gpio_06.dtsi" 1
# 12 "/mnt/080b9fba-139f-40aa-b1d1-529119d8c495/develop/Android/Kernel/android_kernel_samsung_universal9610/arch/arm64/boot/dts/exynos/exynos9610-a50_swa_open_gpio_06.dtsi"
# 1 "/mnt/080b9fba-139f-40aa-b1d1-529119d8c495/develop/Android/Kernel/android_kernel_samsung_universal9610/arch/arm64/boot/dts/exynos/exynos_gpio_config_macros.dtsi" 1
# 13 "/mnt/080b9fba-139f-40aa-b1d1-529119d8c495/develop/Android/Kernel/android_kernel_samsung_universal9610/arch/arm64/boot/dts/exynos/exynos9610-a50_swa_open_gpio_06.dtsi" 2
# 21 "/mnt/080b9fba-139f-40aa-b1d1-529119d8c495/develop/Android/Kernel/android_kernel_samsung_universal9610/arch/arm64/boot/dts/exynos/exynos9610-a50_swa_open_gpio_06.dtsi"
&pinctrl_0 {
 pinctrl-names = "default";
 pinctrl-0 = <&initial0>;
 initial0: initial-state {
  gpa0-6 { samsung,pins = "gpa0-6"; samsung,pin-function = <0>; samsung,pin-pud = <1>; };
  gpa2-5 { samsung,pins = "gpa2-5"; samsung,pin-function = <0>; samsung,pin-pud = <1>; };
  etc0-5 { samsung,pins = "etc0-5"; samsung,pin-function = <0>; samsung,pin-pud = <1>; };
 };
};





&pinctrl_1 {
 pinctrl-names = "default","sleep";
 pinctrl-0 = <&initial1>;
 pinctrl-1 = <&sleep1>;
 initial1: initial-state {
  gpm0-0 { samsung,pins = "gpm0-0"; samsung,pin-function = <0>; samsung,pin-pud = <1>; };
  gpm1-0 { samsung,pins = "gpm1-0"; samsung,pin-function = <0>; samsung,pin-pud = <1>; };
  gpm6-0 { samsung,pins = "gpm6-0"; samsung,pin-function = <0>; samsung,pin-pud = <1>; };
  gpm7-0 { samsung,pins = "gpm7-0"; samsung,pin-function = <0>; samsung,pin-pud = <1>; };
  gpm15-0 { samsung,pins = "gpm15-0"; samsung,pin-function = <0>; samsung,pin-pud = <1>; };
 };
 sleep1: sleep-state {
  gpm0-0 { samsung,pins = "gpm0-0"; samsung,pin-con-pdn = <2>; samsung,pin-pud-pdn = <1>; };
  gpm1-0 { samsung,pins = "gpm1-0"; samsung,pin-con-pdn = <2>; samsung,pin-pud-pdn = <1>; };
  gpm6-0 { samsung,pins = "gpm6-0"; samsung,pin-con-pdn = <2>; samsung,pin-pud-pdn = <1>; };
  gpm7-0 { samsung,pins = "gpm7-0"; samsung,pin-con-pdn = <2>; samsung,pin-pud-pdn = <1>; };
  gpm12-0 { samsung,pins = "gpm12-0"; samsung,pin-con-pdn = <0>; samsung,pin-pud-pdn = <1>; };
  gpm13-0 { samsung,pins = "gpm13-0"; samsung,pin-con-pdn = <0>; samsung,pin-pud-pdn = <1>; };
  gpm14-0 { samsung,pins = "gpm14-0"; samsung,pin-con-pdn = <0>; samsung,pin-pud-pdn = <1>; };
  gpm15-0 { samsung,pins = "gpm15-0"; samsung,pin-con-pdn = <2>; samsung,pin-pud-pdn = <1>; };
 };
};





&pinctrl_2 {
 pinctrl-names = "sleep";
 pinctrl-0 = <&sleep2>;
 sleep2: sleep-state {
  gpb2-0 { samsung,pins = "gpb2-0"; samsung,pin-con-pdn = <2>; samsung,pin-pud-pdn = <1>; };
  gpb2-1 { samsung,pins = "gpb2-1"; samsung,pin-con-pdn = <2>; samsung,pin-pud-pdn = <1>; };
  gpb2-2 { samsung,pins = "gpb2-2"; samsung,pin-con-pdn = <2>; samsung,pin-pud-pdn = <1>; };
  gpb2-3 { samsung,pins = "gpb2-3"; samsung,pin-con-pdn = <2>; samsung,pin-pud-pdn = <1>; };
  gpb2-4 { samsung,pins = "gpb2-4"; samsung,pin-con-pdn = <2>; samsung,pin-pud-pdn = <1>; };
 };
};





&pinctrl_3 {
 pinctrl-names = "default","sleep";
 pinctrl-0 = <&initial3>;
 pinctrl-1 = <&sleep3>;
 initial3: initial-state {
  gpf0-2 { samsung,pins = "gpf0-2"; samsung,pin-function = <0>; samsung,pin-pud = <1>; };
  gpf0-3 { samsung,pins = "gpf0-3"; samsung,pin-function = <0>; samsung,pin-pud = <1>; };
  gpf1-0 { samsung,pins = "gpf1-0"; samsung,pin-function = <0>; samsung,pin-pud = <1>; };
  gpf1-1 { samsung,pins = "gpf1-1"; samsung,pin-function = <0>; samsung,pin-pud = <1>; };
  gpf1-2 { samsung,pins = "gpf1-2"; samsung,pin-function = <0>; samsung,pin-pud = <1>; };
  gpf1-3 { samsung,pins = "gpf1-3"; samsung,pin-function = <0>; samsung,pin-pud = <1>; };
  gpf1-4 { samsung,pins = "gpf1-4"; samsung,pin-function = <0>; samsung,pin-pud = <1>; };
  gpf1-5 { samsung,pins = "gpf1-5"; samsung,pin-function = <0>; samsung,pin-pud = <1>; };
  gpf1-6 { samsung,pins = "gpf1-6"; samsung,pin-function = <0>; samsung,pin-pud = <1>; };
  gpf1-7 { samsung,pins = "gpf1-7"; samsung,pin-function = <0>; samsung,pin-pud = <1>; };
 };
 sleep3: sleep-state {
  gpf0-2 { samsung,pins = "gpf0-2"; samsung,pin-con-pdn = <2>; samsung,pin-pud-pdn = <1>; };
  gpf0-3 { samsung,pins = "gpf0-3"; samsung,pin-con-pdn = <2>; samsung,pin-pud-pdn = <1>; };
  gpf1-0 { samsung,pins = "gpf1-0"; samsung,pin-con-pdn = <2>; samsung,pin-pud-pdn = <1>; };
  gpf1-1 { samsung,pins = "gpf1-1"; samsung,pin-con-pdn = <2>; samsung,pin-pud-pdn = <1>; };
  gpf1-2 { samsung,pins = "gpf1-2"; samsung,pin-con-pdn = <2>; samsung,pin-pud-pdn = <1>; };
  gpf1-3 { samsung,pins = "gpf1-3"; samsung,pin-con-pdn = <2>; samsung,pin-pud-pdn = <1>; };
  gpf1-4 { samsung,pins = "gpf1-4"; samsung,pin-con-pdn = <2>; samsung,pin-pud-pdn = <1>; };
  gpf1-5 { samsung,pins = "gpf1-5"; samsung,pin-con-pdn = <2>; samsung,pin-pud-pdn = <1>; };
  gpf1-6 { samsung,pins = "gpf1-6"; samsung,pin-con-pdn = <2>; samsung,pin-pud-pdn = <1>; };
  gpf1-7 { samsung,pins = "gpf1-7"; samsung,pin-con-pdn = <2>; samsung,pin-pud-pdn = <1>; };
 };
};







&pinctrl_4 {
 pinctrl-names = "default","sleep";
 pinctrl-0 = <&initial4>;
 pinctrl-1 = <&sleep4>;
 initial4: initial-state {
  gpp0-4 { samsung,pins = "gpp0-4"; samsung,pin-function = <0>; samsung,pin-pud = <0>; };
  gpp0-5 { samsung,pins = "gpp0-5"; samsung,pin-function = <0>; samsung,pin-pud = <0>; };

  gpp2-0 { samsung,pins = "gpp2-0"; samsung,pin-function = <0>; samsung,pin-pud = <1>; };
  gpp2-1 { samsung,pins = "gpp2-1"; samsung,pin-function = <0>; samsung,pin-pud = <1>; };
  gpp2-2 { samsung,pins = "gpp2-2"; samsung,pin-function = <0>; samsung,pin-pud = <1>; };
  gpp2-3 { samsung,pins = "gpp2-3"; samsung,pin-function = <0>; samsung,pin-pud = <1>; };

  gpc1-4 { samsung,pins = "gpc1-4"; samsung,pin-function = <0>; samsung,pin-pud = <1>; };
  gpc1-5 { samsung,pins = "gpc1-5"; samsung,pin-function = <0>; samsung,pin-pud = <1>; };
  gpc1-6 { samsung,pins = "gpc1-6"; samsung,pin-function = <0>; samsung,pin-pud = <1>; };
  gpc1-7 { samsung,pins = "gpc1-7"; samsung,pin-function = <0>; samsung,pin-pud = <1>; };

  gpc2-4 { samsung,pins = "gpc2-4"; samsung,pin-function = <0>; samsung,pin-pud = <1>; };

  gpg0-1 { samsung,pins = "gpg0-1"; samsung,pin-function = <0>; samsung,pin-pud = <0>; };
  gpg0-7 { samsung,pins = "gpg0-7"; samsung,pin-function = <0>; samsung,pin-pud = <1>; };
  gpg1-4 { samsung,pins = "gpg1-4"; samsung,pin-function = <0>; samsung,pin-pud = <1>; };
  gpg1-5 { samsung,pins = "gpg1-5"; samsung,pin-function = <1>; samsung,pin-pud = <0>; samsung,pin-drv = <0x0>; samsung,pin-val = <1>; };
  gpg1-6 { samsung,pins = "gpg1-6"; samsung,pin-function = <0>; samsung,pin-pud = <1>; };

  gpg2-2 { samsung,pins = "gpg2-2"; samsung,pin-function = <0>; samsung,pin-pud = <0>; };
  gpg2-5 { samsung,pins = "gpg2-5"; samsung,pin-function = <0>; samsung,pin-pud = <0>; };
  gpg2-6 { samsung,pins = "gpg2-6"; samsung,pin-function = <0>; samsung,pin-pud = <0>; };

  gpg3-1 { samsung,pins = "gpg3-1"; samsung,pin-function = <1>; samsung,pin-pud = <0>; samsung,pin-drv = <0x0>; samsung,pin-val = <1>; };
  gpg3-2 { samsung,pins = "gpg3-2"; samsung,pin-function = <0>; samsung,pin-pud = <0>; };
  gpg3-3 { samsung,pins = "gpg3-3"; samsung,pin-function = <0>; samsung,pin-pud = <0>; };
  gpg3-4 { samsung,pins = "gpg3-4"; samsung,pin-function = <0>; samsung,pin-pud = <0>; };
  gpg3-5 { samsung,pins = "gpg3-5"; samsung,pin-function = <0>; samsung,pin-pud = <0>; };

  gpg4-1 { samsung,pins = "gpg4-1"; samsung,pin-function = <0>; samsung,pin-pud = <1>; };
 };
 sleep4: sleep-state {
  gpp0-0 { samsung,pins = "gpp0-0"; samsung,pin-con-pdn = <2>; samsung,pin-pud-pdn = <0>; };
  gpp0-1 { samsung,pins = "gpp0-1"; samsung,pin-con-pdn = <2>; samsung,pin-pud-pdn = <0>; };
  gpp0-2 { samsung,pins = "gpp0-2"; samsung,pin-con-pdn = <2>; samsung,pin-pud-pdn = <0>; };
  gpp0-3 { samsung,pins = "gpp0-3"; samsung,pin-con-pdn = <2>; samsung,pin-pud-pdn = <0>; };
  gpp0-4 { samsung,pins = "gpp0-4"; samsung,pin-con-pdn = <2>; samsung,pin-pud-pdn = <0>; };
  gpp0-5 { samsung,pins = "gpp0-5"; samsung,pin-con-pdn = <2>; samsung,pin-pud-pdn = <0>; };
  gpp0-6 { samsung,pins = "gpp0-6"; samsung,pin-con-pdn = <2>; samsung,pin-pud-pdn = <0>; };
  gpp0-7 { samsung,pins = "gpp0-7"; samsung,pin-con-pdn = <2>; samsung,pin-pud-pdn = <0>; };

  gpp1-0 { samsung,pins = "gpp1-0"; samsung,pin-con-pdn = <2>; samsung,pin-pud-pdn = <0>; };
  gpp1-1 { samsung,pins = "gpp1-1"; samsung,pin-con-pdn = <2>; samsung,pin-pud-pdn = <0>; };
  gpp1-2 { samsung,pins = "gpp1-2"; samsung,pin-con-pdn = <2>; samsung,pin-pud-pdn = <0>; };
  gpp1-3 { samsung,pins = "gpp1-3"; samsung,pin-con-pdn = <2>; samsung,pin-pud-pdn = <0>; };
  gpp1-4 { samsung,pins = "gpp1-4"; samsung,pin-con-pdn = <2>; samsung,pin-pud-pdn = <0>; };
  gpp1-5 { samsung,pins = "gpp1-5"; samsung,pin-con-pdn = <2>; samsung,pin-pud-pdn = <0>; };

  gpp2-0 { samsung,pins = "gpp2-0"; samsung,pin-con-pdn = <2>; samsung,pin-pud-pdn = <1>; };
  gpp2-1 { samsung,pins = "gpp2-1"; samsung,pin-con-pdn = <2>; samsung,pin-pud-pdn = <1>; };
  gpp2-2 { samsung,pins = "gpp2-2"; samsung,pin-con-pdn = <2>; samsung,pin-pud-pdn = <1>; };
  gpp2-3 { samsung,pins = "gpp2-3"; samsung,pin-con-pdn = <2>; samsung,pin-pud-pdn = <1>; };

  gpc1-2 { samsung,pins = "gpc1-2"; samsung,pin-con-pdn = <2>; samsung,pin-pud-pdn = <1>; };
  gpc1-3 { samsung,pins = "gpc1-3"; samsung,pin-con-pdn = <2>; samsung,pin-pud-pdn = <1>; };
  gpc1-4 { samsung,pins = "gpc1-4"; samsung,pin-con-pdn = <2>; samsung,pin-pud-pdn = <1>; };
  gpc1-5 { samsung,pins = "gpc1-5"; samsung,pin-con-pdn = <2>; samsung,pin-pud-pdn = <1>; };
  gpc1-6 { samsung,pins = "gpc1-6"; samsung,pin-con-pdn = <2>; samsung,pin-pud-pdn = <1>; };
  gpc1-7 { samsung,pins = "gpc1-7"; samsung,pin-con-pdn = <2>; samsung,pin-pud-pdn = <1>; };

  gpc2-2 { samsung,pins = "gpc2-2"; samsung,pin-con-pdn = <2>; samsung,pin-pud-pdn = <1>; };
  gpc2-4 { samsung,pins = "gpc2-4"; samsung,pin-con-pdn = <2>; samsung,pin-pud-pdn = <1>; };

  gpg0-1 { samsung,pins = "gpg0-1"; samsung,pin-con-pdn = <2>; samsung,pin-pud-pdn = <0>; };
  gpg0-5 { samsung,pins = "gpg0-5"; samsung,pin-con-pdn = <3>; samsung,pin-pud-pdn = <0>; };
  gpg0-6 { samsung,pins = "gpg0-6"; samsung,pin-con-pdn = <0>; samsung,pin-pud-pdn = <1>; };
  gpg0-7 { samsung,pins = "gpg0-7"; samsung,pin-con-pdn = <2>; samsung,pin-pud-pdn = <1>; };
  gpg1-2 { samsung,pins = "gpg1-2"; samsung,pin-con-pdn = <3>; samsung,pin-pud-pdn = <0>; };
  gpg1-3 { samsung,pins = "gpg1-3"; samsung,pin-con-pdn = <3>; samsung,pin-pud-pdn = <0>; };
  gpg1-4 { samsung,pins = "gpg1-4"; samsung,pin-con-pdn = <2>; samsung,pin-pud-pdn = <1>; };
  gpg1-5 { samsung,pins = "gpg1-5"; samsung,pin-con-pdn = <1>; samsung,pin-pud-pdn = <0>; };
  gpg1-6 { samsung,pins = "gpg1-6"; samsung,pin-con-pdn = <2>; samsung,pin-pud-pdn = <1>; };

  gpg2-1 { samsung,pins = "gpg2-1"; samsung,pin-con-pdn = <3>; samsung,pin-pud-pdn = <0>; };
  gpg2-2 { samsung,pins = "gpg2-2"; samsung,pin-con-pdn = <2>; samsung,pin-pud-pdn = <0>; };
  gpg2-3 { samsung,pins = "gpg2-3"; samsung,pin-con-pdn = <3>; samsung,pin-pud-pdn = <1>; };
  gpg2-4 { samsung,pins = "gpg2-4"; samsung,pin-con-pdn = <3>; samsung,pin-pud-pdn = <0>; };
  gpg2-5 { samsung,pins = "gpg2-5"; samsung,pin-con-pdn = <2>; samsung,pin-pud-pdn = <0>; };
  gpg2-6 { samsung,pins = "gpg2-6"; samsung,pin-con-pdn = <2>; samsung,pin-pud-pdn = <0>; };

  gpg3-0 { samsung,pins = "gpg3-0"; samsung,pin-con-pdn = <0>; samsung,pin-pud-pdn = <1>; };
  gpg3-1 { samsung,pins = "gpg3-1"; samsung,pin-con-pdn = <3>; samsung,pin-pud-pdn = <0>; };
  gpg3-2 { samsung,pins = "gpg3-2"; samsung,pin-con-pdn = <2>; samsung,pin-pud-pdn = <0>; };
  gpg3-3 { samsung,pins = "gpg3-3"; samsung,pin-con-pdn = <2>; samsung,pin-pud-pdn = <0>; };
  gpg3-4 { samsung,pins = "gpg3-4"; samsung,pin-con-pdn = <2>; samsung,pin-pud-pdn = <0>; };
  gpg3-5 { samsung,pins = "gpg3-5"; samsung,pin-con-pdn = <2>; samsung,pin-pud-pdn = <0>; };

  gpg4-0 { samsung,pins = "gpg4-0"; samsung,pin-con-pdn = <3>; samsung,pin-pud-pdn = <0>; };
  gpg4-1 { samsung,pins = "gpg4-1"; samsung,pin-con-pdn = <2>; samsung,pin-pud-pdn = <1>; };
  gpg4-2 { samsung,pins = "gpg4-2"; samsung,pin-con-pdn = <3>; samsung,pin-pud-pdn = <0>; };
 };
};
# 20 "/mnt/080b9fba-139f-40aa-b1d1-529119d8c495/develop/Android/Kernel/android_kernel_samsung_universal9610/arch/arm64/boot/dts/exynos/exynos9610-a50_swa_open_06.dts" 2

/ {
 compatible = "samsung, A50 SWA OPEN 06", "samsung,EXYNOS9610";
 dtbo-hw_rev = <6>;
 dtbo-hw_rev_end = <255>;

 fragment@model {
  target-path = "/";
  __overlay__ {
   #address-cells = <2>;
   #size-cells = <1>;

   model = "Samsung A50 SWA OPEN rev04 board based on Exynos9610";

   mif_pdata {


    gpios = <&gpg3 2 0>, <&gpg3 3 0>, <&gpg3 4 0>, <&gpg3 5 0>;
    pinctrl-names = "default";
   };

   dwmmc2@13550000 {
    pinctrl-names = "default";
    card-detect = <&gpa2 4 0xf>;
   };

   sec_vib {
    compatible = "sec_vib";
    sec_vib_pdata {
     status = "okay";
     sec_vib,max_timeout = <10000>;
     sec_vib,ldo_type = <1>;
     sec_vib,ldo_en = <&gpa2 1 0>;
    };
   };

  };
 };
};

&pinctrl_0 {
 earant_det: earant-det {
  samsung,pins ="gpa1-4";
  samsung,pin-function = <0>;
  samsung,pin-pud = <0>;
 };

 dwmmc2_cd_ext_irq: dwmmc2_cd_ext_irq {
  samsung,pins = "gpa2-4";
  samsung,pin-function = <0xf>;
  samsung,pin-pud = <0>;
  samsung,pin-drv = <3>;
 };

 grip_int: grip-int {
  samsung,pins = "gpa2-7";
  samsung,pin-function = <0xf>;
  samsung,pin-pud = <0>;
 };
};

&pinctrl_4 {
 grip_i2c: grip-i2c {
  samsung,pins = "gpp1-2", "gpp1-3";
  samsung,pin-function = <2>;
  samsung,pin-pud = <0>;
 };

 grip_gpio: grip-gpio {
  samsung,pins = "gpp1-2", "gpp1-3";
  samsung,pin-function = <0>;
  samsung,pin-pud = <0>;
 };
};
